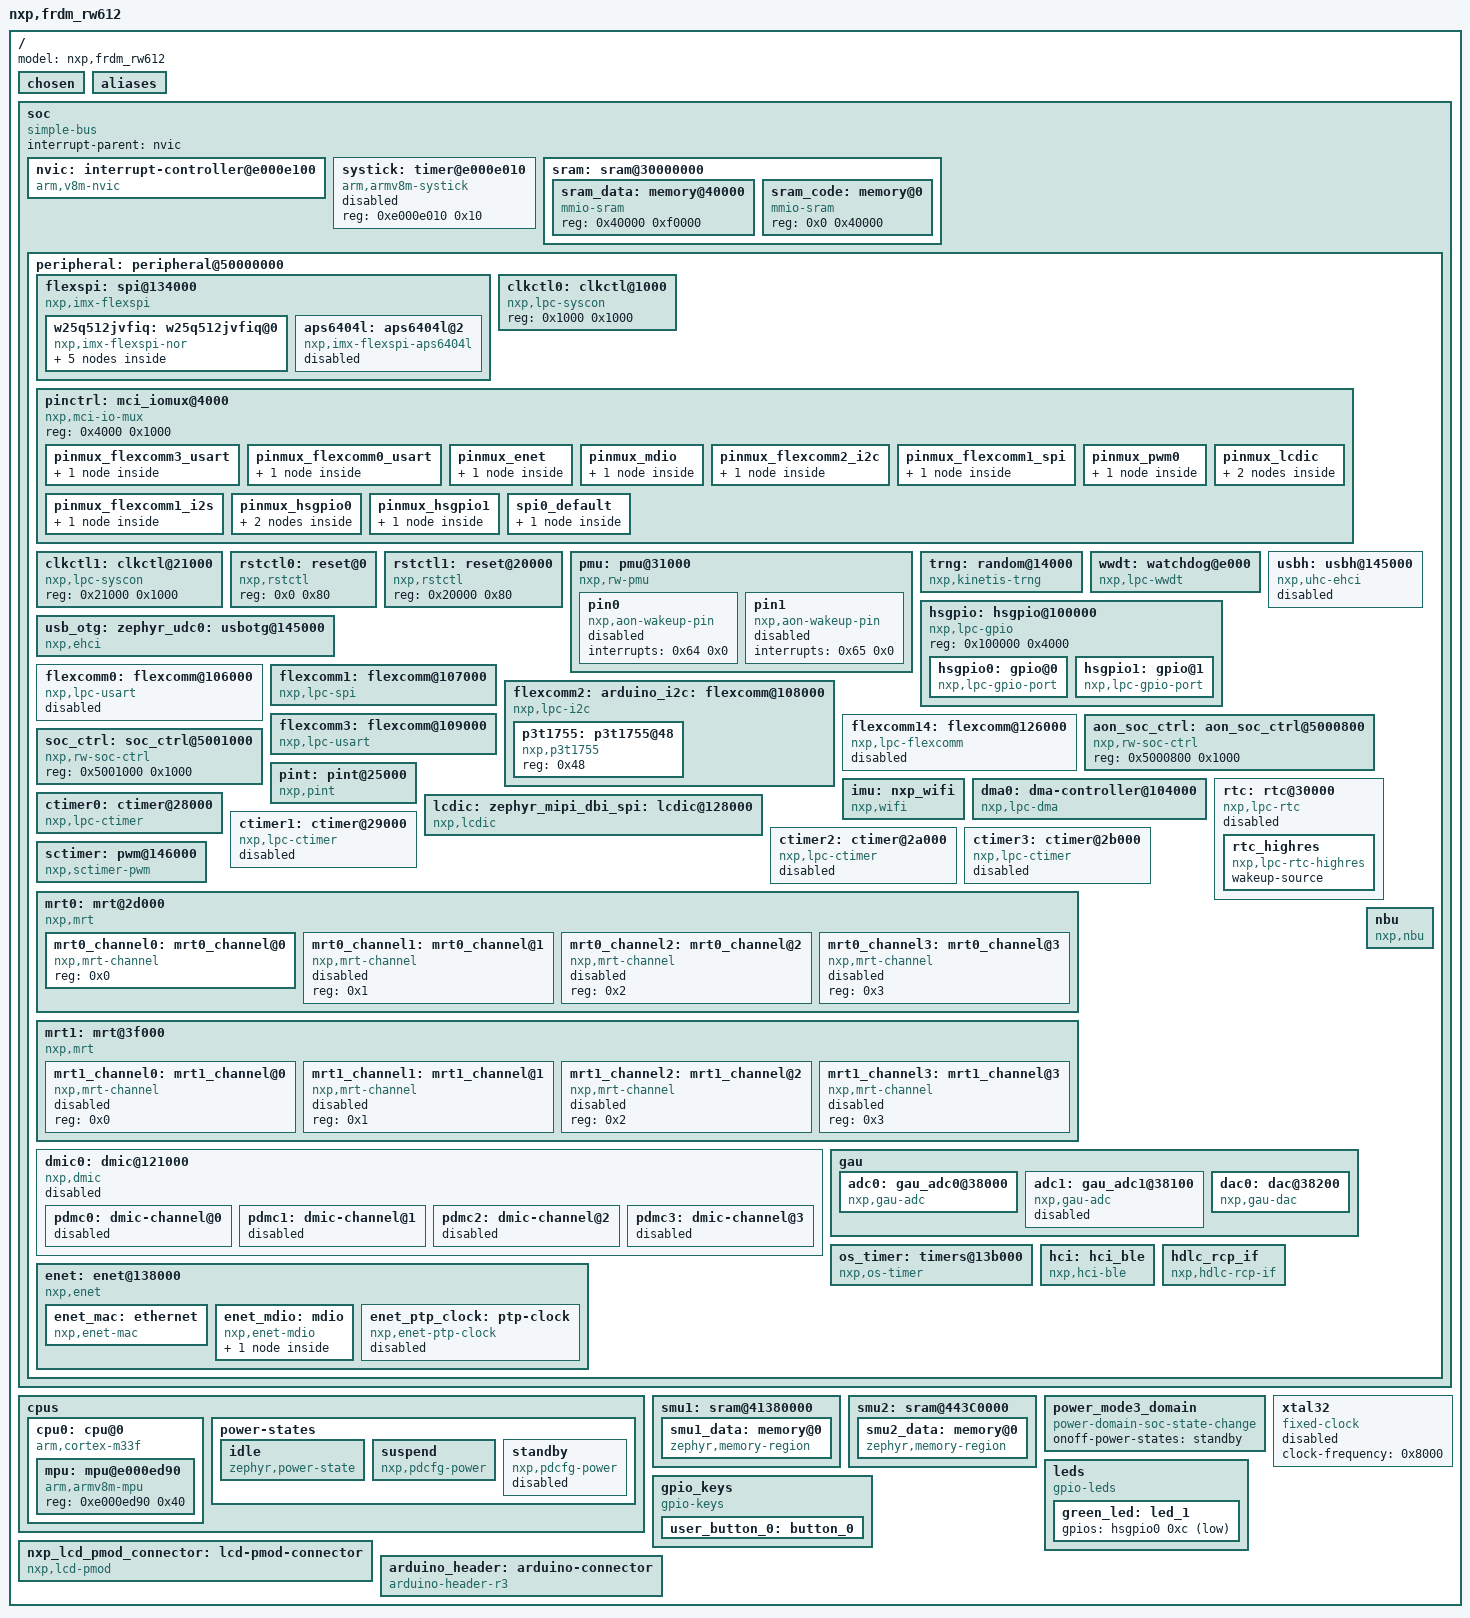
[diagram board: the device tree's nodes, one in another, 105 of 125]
/dts-v1/;

/* node '/' defined in zephyr/dts/common/skeleton.dtsi:9 */
/ {
	#address-cells = < 0x1 >; /* in zephyr/dts/common/skeleton.dtsi:10 */
	#size-cells = < 0x1 >;    /* in zephyr/dts/common/skeleton.dtsi:11 */
	model = "nxp,frdm_rw612"; /* in zephyr/boards/nxp/frdm_rw612/frdm_rw612_common.dtsi:12 */

	/* node '/chosen' defined in zephyr/dts/common/skeleton.dtsi:12 */
	chosen {
		zephyr,entropy = &trng;                   /* in zephyr/dts/arm/nxp/nxp_rw6xx_common.dtsi:18 */
		zephyr,nbu = &nbu;                        /* in zephyr/dts/arm/nxp/nxp_rw6xx_common.dtsi:19 */
		zephyr,bt-hci = &hci;                     /* in zephyr/dts/arm/nxp/nxp_rw6xx_common.dtsi:20 */
		zephyr,hdlc-rcp-if = &hdlc_rcp_if;        /* in zephyr/dts/arm/nxp/nxp_rw6xx_common.dtsi:21 */
		zephyr,sram = &sram_data;                 /* in zephyr/boards/nxp/frdm_rw612/frdm_rw612_common.dtsi:25 */
		zephyr,flash = &w25q512jvfiq;             /* in zephyr/boards/nxp/frdm_rw612/frdm_rw612_common.dtsi:26 */
		zephyr,console = &flexcomm3;              /* in zephyr/boards/nxp/frdm_rw612/frdm_rw612_common.dtsi:27 */
		zephyr,shell-uart = &flexcomm3;           /* in zephyr/boards/nxp/frdm_rw612/frdm_rw612_common.dtsi:28 */
		zephyr,flash-controller = &w25q512jvfiq;  /* in zephyr/boards/nxp/frdm_rw612/frdm_rw612_common.dtsi:29 */
		zephyr,code-partition = &slot0_partition; /* in zephyr/boards/nxp/frdm_rw612/frdm_rw612_common.dtsi:30 */
		zephyr,uart-mcumgr = &flexcomm3;          /* in zephyr/boards/nxp/frdm_rw612/frdm_rw612_common.dtsi:31 */
	};

	/* node '/aliases' defined in zephyr/dts/common/skeleton.dtsi:13 */
	aliases {
		led0 = &green_led;        /* in zephyr/boards/nxp/frdm_rw612/frdm_rw612_common.dtsi:15 */
		watchdog0 = &wwdt;        /* in zephyr/boards/nxp/frdm_rw612/frdm_rw612_common.dtsi:16 */
		usart-0 = &flexcomm3;     /* in zephyr/boards/nxp/frdm_rw612/frdm_rw612_common.dtsi:17 */
		i2c-0 = &flexcomm2;       /* in zephyr/boards/nxp/frdm_rw612/frdm_rw612_common.dtsi:18 */
		pwm-0 = &sctimer;         /* in zephyr/boards/nxp/frdm_rw612/frdm_rw612_common.dtsi:19 */
		sw0 = &user_button_0;     /* in zephyr/boards/nxp/frdm_rw612/frdm_rw612_common.dtsi:20 */
		ambient-temp0 = &p3t1755; /* in zephyr/boards/nxp/frdm_rw612/frdm_rw612_common.dtsi:21 */
		spi0 = &flexcomm1;        /* in ../dbus_porting/zephyr_dbus_driver/boards/frdm_rw612.overlay:3 */
	};

	/* node '/soc' defined in zephyr/dts/arm/armv8-m.dtsi:6 */
	soc {
		#address-cells = < 0x1 >;     /* in zephyr/dts/arm/armv8-m.dtsi:7 */
		#size-cells = < 0x1 >;        /* in zephyr/dts/arm/armv8-m.dtsi:8 */
		compatible = "simple-bus";    /* in zephyr/dts/arm/armv8-m.dtsi:9 */
		interrupt-parent = < &nvic >; /* in zephyr/dts/arm/armv8-m.dtsi:10 */
		ranges;                       /* in zephyr/dts/arm/armv8-m.dtsi:11 */

		/* node '/soc/interrupt-controller@e000e100' defined in zephyr/dts/arm/armv8-m.dtsi:13 */
		nvic: interrupt-controller@e000e100 {
			#address-cells = < 0x1 >;            /* in zephyr/dts/arm/armv8-m.dtsi:14 */
			compatible = "arm,v8m-nvic";         /* in zephyr/dts/arm/armv8-m.dtsi:15 */
			reg = < 0xe000e100 0xc00 >;          /* in zephyr/dts/arm/armv8-m.dtsi:16 */
			interrupt-controller;                /* in zephyr/dts/arm/armv8-m.dtsi:17 */
			#interrupt-cells = < 0x2 >;          /* in zephyr/dts/arm/armv8-m.dtsi:18 */
			arm,num-irq-priority-bits = < 0x3 >; /* in zephyr/dts/arm/nxp/nxp_rw6xx_common.dtsi:659 */
			phandle = < 0x1 >;                   /* in zephyr/dts/arm/armv8-m.dtsi:10 */
		};

		/* node '/soc/timer@e000e010' defined in zephyr/dts/arm/armv8-m.dtsi:21 */
		systick: timer@e000e010 {
			compatible = "arm,armv8m-systick"; /* in zephyr/dts/arm/armv8-m.dtsi:22 */
			reg = < 0xe000e010 0x10 >;         /* in zephyr/dts/arm/armv8-m.dtsi:23 */
			status = "disabled";               /* in zephyr/boards/nxp/frdm_rw612/frdm_rw612_common.dtsi:242 */
		};

		/* node '/soc/sram@30000000' defined in zephyr/dts/arm/nxp/nxp_rw6xx.dtsi:12 */
		sram: sram@30000000 {
			ranges = < 0x20000000 0x30000000 0x130000 0x0 0x10000000 0x130000 >; /* in zephyr/dts/arm/nxp/nxp_rw6xx.dtsi:13 */
			#address-cells = < 0x1 >;                                            /* in zephyr/dts/arm/nxp/nxp_rw6xx_common.dtsi:101 */
			#size-cells = < 0x1 >;                                               /* in zephyr/dts/arm/nxp/nxp_rw6xx_common.dtsi:102 */

			/* node '/soc/sram@30000000/memory@40000' defined in zephyr/dts/arm/nxp/nxp_rw6xx_common.dtsi:109 */
			sram_data: memory@40000 {
				compatible = "mmio-sram";  /* in zephyr/dts/arm/nxp/nxp_rw6xx_common.dtsi:110 */
				reg = < 0x40000 0xf0000 >; /* in zephyr/dts/arm/nxp/nxp_rw6xx_common.dtsi:111 */
			};

			/* node '/soc/sram@30000000/memory@0' defined in zephyr/dts/arm/nxp/nxp_rw6xx_common.dtsi:114 */
			sram_code: memory@0 {
				compatible = "mmio-sram"; /* in zephyr/dts/arm/nxp/nxp_rw6xx_common.dtsi:115 */
				reg = < 0x0 0x40000 >;    /* in zephyr/dts/arm/nxp/nxp_rw6xx_common.dtsi:116 */
			};
		};

		/* node '/soc/peripheral@50000000' defined in zephyr/dts/arm/nxp/nxp_rw6xx.dtsi:17 */
		peripheral: peripheral@50000000 {
			ranges = < 0x0 0x50000000 0x10000000 >; /* in zephyr/dts/arm/nxp/nxp_rw6xx.dtsi:18 */
			#address-cells = < 0x1 >;               /* in zephyr/dts/arm/nxp/nxp_rw6xx_common.dtsi:145 */
			#size-cells = < 0x1 >;                  /* in zephyr/dts/arm/nxp/nxp_rw6xx_common.dtsi:146 */

			/* node '/soc/peripheral@50000000/spi@134000' defined in zephyr/dts/arm/nxp/nxp_rw6xx_common.dtsi:148 */
			flexspi: spi@134000 {
				reg = < 0x134000 0x1000 >,
				      < 0x18000000 0x8000000 >; /* in zephyr/dts/arm/nxp/nxp_rw6xx_common.dtsi:149 */
				compatible = "nxp,imx-flexspi"; /* in zephyr/dts/arm/nxp/nxp_rw6xx_common.dtsi:650 */
				interrupts = < 0x2a 0x0 >;      /* in zephyr/dts/arm/nxp/nxp_rw6xx_common.dtsi:652 */
				#address-cells = < 0x1 >;       /* in zephyr/dts/arm/nxp/nxp_rw6xx_common.dtsi:653 */
				#size-cells = < 0x0 >;          /* in zephyr/dts/arm/nxp/nxp_rw6xx_common.dtsi:654 */
				clocks = < &clkctl1 0xa00 >;    /* in zephyr/dts/arm/nxp/nxp_rw6xx_common.dtsi:655 */
				status = "okay";                /* in zephyr/boards/nxp/frdm_rw612/frdm_rw612_common.dtsi:117 */
				ahb-bufferable;                 /* in zephyr/boards/nxp/frdm_rw612/frdm_rw612_common.dtsi:118 */
				ahb-prefetch;                   /* in zephyr/boards/nxp/frdm_rw612/frdm_rw612_common.dtsi:119 */
				ahb-cacheable;                  /* in zephyr/boards/nxp/frdm_rw612/frdm_rw612_common.dtsi:120 */
				ahb-read-addr-opt;              /* in zephyr/boards/nxp/frdm_rw612/frdm_rw612_common.dtsi:121 */
				ahb-boundary = "1024";          /* in zephyr/boards/nxp/frdm_rw612/frdm_rw612_common.dtsi:122 */
				rx-clock-source = < 0x1 >;      /* in zephyr/boards/nxp/frdm_rw612/frdm_rw612_common.dtsi:123 */
				rx-clock-source-b = < 0x1 >;    /* in zephyr/boards/nxp/frdm_rw612/frdm_rw612_common.dtsi:124 */

				/* node '/soc/peripheral@50000000/spi@134000/w25q512jvfiq@0' defined in zephyr/boards/nxp/frdm_rw612/frdm_rw612_common.dtsi:126 */
				w25q512jvfiq: w25q512jvfiq@0 {
					compatible = "nxp,imx-flexspi-nor"; /* in zephyr/boards/nxp/frdm_rw612/frdm_rw612_common.dtsi:127 */
					reg = < 0x0 >;                      /* in zephyr/boards/nxp/frdm_rw612/frdm_rw612_common.dtsi:128 */
					size = < 0x20000000 >;              /* in zephyr/boards/nxp/frdm_rw612/frdm_rw612_common.dtsi:129 */
					status = "okay";                    /* in zephyr/boards/nxp/frdm_rw612/frdm_rw612_common.dtsi:130 */
					jedec-id = [ EF 40 20 ];            /* in zephyr/boards/nxp/frdm_rw612/frdm_rw612_common.dtsi:131 */
					erase-block-size = < 0x1000 >;      /* in zephyr/boards/nxp/frdm_rw612/frdm_rw612_common.dtsi:132 */
					write-block-size = < 0x1 >;         /* in zephyr/boards/nxp/frdm_rw612/frdm_rw612_common.dtsi:133 */
					spi-max-frequency = < 0x632ea00 >;  /* in zephyr/boards/nxp/frdm_rw612/frdm_rw612_common.dtsi:134 */

					/* node '/soc/peripheral@50000000/spi@134000/w25q512jvfiq@0/partitions' defined in zephyr/boards/nxp/frdm_rw612/frdm_rw612_common.dtsi:136 */
					partitions {
						compatible = "fixed-partitions"; /* in zephyr/boards/nxp/frdm_rw612/frdm_rw612_common.dtsi:137 */
						#address-cells = < 0x1 >;        /* in zephyr/boards/nxp/frdm_rw612/frdm_rw612_common.dtsi:138 */
						#size-cells = < 0x1 >;           /* in zephyr/boards/nxp/frdm_rw612/frdm_rw612_common.dtsi:139 */

						/* node '/soc/peripheral@50000000/spi@134000/w25q512jvfiq@0/partitions/partition@0' defined in zephyr/boards/nxp/frdm_rw612/frdm_rw612_common.dtsi:145 */
						boot_partition: partition@0 {
							label = "mcuboot";     /* in zephyr/boards/nxp/frdm_rw612/frdm_rw612_common.dtsi:146 */
							reg = < 0x0 0x20000 >; /* in zephyr/boards/nxp/frdm_rw612/frdm_rw612_common.dtsi:147 */
						};

						/* node '/soc/peripheral@50000000/spi@134000/w25q512jvfiq@0/partitions/partition@20000' defined in zephyr/boards/nxp/frdm_rw612/frdm_rw612_common.dtsi:149 */
						slot0_partition: partition@20000 {
							label = "image-0";          /* in zephyr/boards/nxp/frdm_rw612/frdm_rw612_common.dtsi:150 */
							reg = < 0x20000 0x300000 >; /* in zephyr/boards/nxp/frdm_rw612/frdm_rw612_common.dtsi:151 */
						};

						/* node '/soc/peripheral@50000000/spi@134000/w25q512jvfiq@0/partitions/partition@320000' defined in zephyr/boards/nxp/frdm_rw612/frdm_rw612_common.dtsi:153 */
						slot1_partition: partition@320000 {
							label = "image-1";           /* in zephyr/boards/nxp/frdm_rw612/frdm_rw612_common.dtsi:154 */
							reg = < 0x320000 0x300000 >; /* in zephyr/boards/nxp/frdm_rw612/frdm_rw612_common.dtsi:155 */
						};

						/* node '/soc/peripheral@50000000/spi@134000/w25q512jvfiq@0/partitions/partition@620000' defined in zephyr/boards/nxp/frdm_rw612/frdm_rw612_common.dtsi:157 */
						storage_partition: partition@620000 {
							label = "storage";            /* in zephyr/boards/nxp/frdm_rw612/frdm_rw612_common.dtsi:158 */
							reg = < 0x620000 0x39e0000 >; /* in zephyr/boards/nxp/frdm_rw612/frdm_rw612_common.dtsi:159 */
						};
					};
				};

				/* node '/soc/peripheral@50000000/spi@134000/aps6404l@2' defined in zephyr/boards/nxp/frdm_rw612/frdm_rw612_common.dtsi:163 */
				aps6404l: aps6404l@2 {
					compatible = "nxp,imx-flexspi-aps6404l"; /* in zephyr/boards/nxp/frdm_rw612/frdm_rw612_common.dtsi:164 */
					size = < 0x4000000 >;                    /* in zephyr/boards/nxp/frdm_rw612/frdm_rw612_common.dtsi:166 */
					reg = < 0x2 >;                           /* in zephyr/boards/nxp/frdm_rw612/frdm_rw612_common.dtsi:167 */
					spi-max-frequency = < 0x67f3540 >;       /* in zephyr/boards/nxp/frdm_rw612/frdm_rw612_common.dtsi:168 */
					status = "disabled";                     /* in zephyr/boards/nxp/frdm_rw612/frdm_rw612_common.dtsi:172 */
					cs-interval-unit = < 0x1 >;              /* in zephyr/boards/nxp/frdm_rw612/frdm_rw612_common.dtsi:173 */
					cs-interval = < 0x2 >;                   /* in zephyr/boards/nxp/frdm_rw612/frdm_rw612_common.dtsi:174 */
					cs-hold-time = < 0x3 >;                  /* in zephyr/boards/nxp/frdm_rw612/frdm_rw612_common.dtsi:175 */
					cs-setup-time = < 0x3 >;                 /* in zephyr/boards/nxp/frdm_rw612/frdm_rw612_common.dtsi:176 */
					data-valid-time = < 0x6 >;               /* in zephyr/boards/nxp/frdm_rw612/frdm_rw612_common.dtsi:177 */
					column-space = < 0x0 >;                  /* in zephyr/boards/nxp/frdm_rw612/frdm_rw612_common.dtsi:178 */
					ahb-write-wait-unit = < 0x2 >;           /* in zephyr/boards/nxp/frdm_rw612/frdm_rw612_common.dtsi:179 */
					ahb-write-wait-interval = < 0x0 >;       /* in zephyr/boards/nxp/frdm_rw612/frdm_rw612_common.dtsi:180 */
				};
			};

			/* node '/soc/peripheral@50000000/clkctl@1000' defined in zephyr/dts/arm/nxp/nxp_rw6xx_common.dtsi:152 */
			clkctl0: clkctl@1000 {
				compatible = "nxp,lpc-syscon"; /* in zephyr/dts/arm/nxp/nxp_rw6xx_common.dtsi:154 */
				reg = < 0x1000 0x1000 >;       /* in zephyr/dts/arm/nxp/nxp_rw6xx_common.dtsi:155 */
				#clock-cells = < 0x1 >;        /* in zephyr/dts/arm/nxp/nxp_rw6xx_common.dtsi:156 */
			};

			/* node '/soc/peripheral@50000000/mci_iomux@4000' defined in zephyr/dts/arm/nxp/nxp_rw6xx_common.dtsi:159 */
			pinctrl: mci_iomux@4000 {
				compatible = "nxp,mci-io-mux"; /* in zephyr/dts/arm/nxp/nxp_rw6xx_common.dtsi:160 */
				reg = < 0x4000 0x1000 >;       /* in zephyr/dts/arm/nxp/nxp_rw6xx_common.dtsi:161 */
				status = "okay";               /* in zephyr/dts/arm/nxp/nxp_rw6xx_common.dtsi:162 */

				/* node '/soc/peripheral@50000000/mci_iomux@4000/pinmux_flexcomm3_usart' defined in zephyr/boards/nxp/frdm_rw612/frdm_rw612-pinctrl.dtsi:10 */
				pinmux_flexcomm3_usart: pinmux_flexcomm3_usart {
					phandle = < 0xd >; /* in zephyr/boards/nxp/frdm_rw612/frdm_rw612_common.dtsi:91 */

					/* node '/soc/peripheral@50000000/mci_iomux@4000/pinmux_flexcomm3_usart/group0' defined in zephyr/boards/nxp/frdm_rw612/frdm_rw612-pinctrl.dtsi:11 */
					group0 {
						pinmux = < 0x49818 0x4981a >; /* in zephyr/boards/nxp/frdm_rw612/frdm_rw612-pinctrl.dtsi:12 */
						slew-rate = "normal";         /* in zephyr/boards/nxp/frdm_rw612/frdm_rw612-pinctrl.dtsi:13 */
					};
				};

				/* node '/soc/peripheral@50000000/mci_iomux@4000/pinmux_flexcomm0_usart' defined in zephyr/boards/nxp/frdm_rw612/frdm_rw612-pinctrl.dtsi:17 */
				pinmux_flexcomm0_usart: pinmux_flexcomm0_usart {
					phandle = < 0xa >; /* in zephyr/boards/nxp/frdm_rw612/frdm_rw612_common.dtsi:100 */

					/* node '/soc/peripheral@50000000/mci_iomux@4000/pinmux_flexcomm0_usart/group0' defined in zephyr/boards/nxp/frdm_rw612/frdm_rw612-pinctrl.dtsi:18 */
					group0 {
						pinmux = < 0x48002 0x48003 >; /* in zephyr/boards/nxp/frdm_rw612/frdm_rw612-pinctrl.dtsi:19 */
						slew-rate = "normal";         /* in zephyr/boards/nxp/frdm_rw612/frdm_rw612-pinctrl.dtsi:20 */
					};
				};

				/* node '/soc/peripheral@50000000/mci_iomux@4000/pinmux_enet' defined in zephyr/boards/nxp/frdm_rw612/frdm_rw612-pinctrl.dtsi:24 */
				pinmux_enet: pinmux_enet {
					phandle = < 0x14 >; /* in zephyr/boards/nxp/frdm_rw612/frdm_rw612_common.dtsi:191 */

					/* node '/soc/peripheral@50000000/mci_iomux@4000/pinmux_enet/group0' defined in zephyr/boards/nxp/frdm_rw612/frdm_rw612-pinctrl.dtsi:25 */
					group0 {
						pinmux = < 0x8099 0xd096 0xd097 0xd0be 0xd0bf 0xc8ba 0xc8bb 0xc8bc 0x315 0x337 >; /* in zephyr/boards/nxp/frdm_rw612/frdm_rw612-pinctrl.dtsi:26 */
						slew-rate = "fast";                                                               /* in zephyr/boards/nxp/frdm_rw612/frdm_rw612-pinctrl.dtsi:31 */
					};
				};

				/* node '/soc/peripheral@50000000/mci_iomux@4000/pinmux_mdio' defined in zephyr/boards/nxp/frdm_rw612/frdm_rw612-pinctrl.dtsi:35 */
				pinmux_mdio: pinmux_mdio {
					phandle = < 0x16 >; /* in zephyr/boards/nxp/frdm_rw612/frdm_rw612_common.dtsi:200 */

					/* node '/soc/peripheral@50000000/mci_iomux@4000/pinmux_mdio/group0' defined in zephyr/boards/nxp/frdm_rw612/frdm_rw612-pinctrl.dtsi:36 */
					group0 {
						pinmux = < 0xd8b8 0xd8b9 >; /* in zephyr/boards/nxp/frdm_rw612/frdm_rw612-pinctrl.dtsi:37 */
						slew-rate = "fast";         /* in zephyr/boards/nxp/frdm_rw612/frdm_rw612-pinctrl.dtsi:38 */
					};
				};

				/* node '/soc/peripheral@50000000/mci_iomux@4000/pinmux_flexcomm2_i2c' defined in zephyr/boards/nxp/frdm_rw612/frdm_rw612-pinctrl.dtsi:42 */
				pinmux_flexcomm2_i2c: pinmux_flexcomm2_i2c {
					phandle = < 0xc >; /* in zephyr/boards/nxp/frdm_rw612/frdm_rw612_common.dtsi:300 */

					/* node '/soc/peripheral@50000000/mci_iomux@4000/pinmux_flexcomm2_i2c/group0' defined in zephyr/boards/nxp/frdm_rw612/frdm_rw612-pinctrl.dtsi:43 */
					group0 {
						pinmux = < 0x21010 0x21011 >; /* in zephyr/boards/nxp/frdm_rw612/frdm_rw612-pinctrl.dtsi:44 */
						slew-rate = "normal";         /* in zephyr/boards/nxp/frdm_rw612/frdm_rw612-pinctrl.dtsi:45 */
						bias-pull-up;                 /* in zephyr/boards/nxp/frdm_rw612/frdm_rw612-pinctrl.dtsi:46 */
					};
				};

				/* node '/soc/peripheral@50000000/mci_iomux@4000/pinmux_flexcomm1_spi' defined in zephyr/boards/nxp/frdm_rw612/frdm_rw612-pinctrl.dtsi:50 */
				pinmux_flexcomm1_spi: pinmux_flexcomm1_spi {
					phandle = < 0xb >; /* in zephyr/boards/nxp/frdm_rw612/frdm_rw612_common.dtsi:287 */

					/* node '/soc/peripheral@50000000/mci_iomux@4000/pinmux_flexcomm1_spi/group0' defined in zephyr/boards/nxp/frdm_rw612/frdm_rw612-pinctrl.dtsi:51 */
					group0 {
						pinmux = < 0x18806 0x18807 0x18808 0x18809 >; /* in zephyr/boards/nxp/frdm_rw612/frdm_rw612-pinctrl.dtsi:52 */
						slew-rate = "ultra";                          /* in zephyr/boards/nxp/frdm_rw612/frdm_rw612-pinctrl.dtsi:53 */
					};
				};

				/* node '/soc/peripheral@50000000/mci_iomux@4000/pinmux_pwm0' defined in zephyr/boards/nxp/frdm_rw612/frdm_rw612-pinctrl.dtsi:57 */
				pinmux_pwm0: pinmux_pwm0 {
					phandle = < 0xf >; /* in zephyr/boards/nxp/frdm_rw612/frdm_rw612_common.dtsi:255 */

					/* node '/soc/peripheral@50000000/mci_iomux@4000/pinmux_pwm0/group0' defined in zephyr/boards/nxp/frdm_rw612/frdm_rw612-pinctrl.dtsi:58 */
					group0 {
						pinmux = < 0x283 >;   /* in zephyr/boards/nxp/frdm_rw612/frdm_rw612-pinctrl.dtsi:59 */
						slew-rate = "normal"; /* in zephyr/boards/nxp/frdm_rw612/frdm_rw612-pinctrl.dtsi:60 */
					};
				};

				/* node '/soc/peripheral@50000000/mci_iomux@4000/pinmux_lcdic' defined in zephyr/boards/nxp/frdm_rw612/frdm_rw612-pinctrl.dtsi:64 */
				pinmux_lcdic: pinmux_lcdic {
					phandle = < 0xe >; /* in zephyr/boards/nxp/frdm_rw612/frdm_rw612_common.dtsi:312 */

					/* node '/soc/peripheral@50000000/mci_iomux@4000/pinmux_lcdic/group0' defined in zephyr/boards/nxp/frdm_rw612/frdm_rw612-pinctrl.dtsi:65 */
					group0 {
						pinmux = < 0x60ad 0x60ae 0x60af 0x60b0 0x60b1 >; /* in zephyr/boards/nxp/frdm_rw612/frdm_rw612-pinctrl.dtsi:66 */
						slew-rate = "ultra";                             /* in zephyr/boards/nxp/frdm_rw612/frdm_rw612-pinctrl.dtsi:71 */
					};

					/* node '/soc/peripheral@50000000/mci_iomux@4000/pinmux_lcdic/group1' defined in zephyr/boards/nxp/frdm_rw612/frdm_rw612-pinctrl.dtsi:73 */
					group1 {
						pinmux = < 0x60ac >;   /* in zephyr/boards/nxp/frdm_rw612/frdm_rw612-pinctrl.dtsi:74 */
						slew-rate = "ultra";   /* in zephyr/boards/nxp/frdm_rw612/frdm_rw612-pinctrl.dtsi:75 */
						sleep-output = "high"; /* in zephyr/boards/nxp/frdm_rw612/frdm_rw612-pinctrl.dtsi:76 */
					};
				};

				/* node '/soc/peripheral@50000000/mci_iomux@4000/pinmux_flexcomm1_i2s' defined in zephyr/boards/nxp/frdm_rw612/frdm_rw612-pinctrl.dtsi:80 */
				pinmux_flexcomm1_i2s: pinmux_flexcomm1_i2s {

					/* node '/soc/peripheral@50000000/mci_iomux@4000/pinmux_flexcomm1_i2s/group0' defined in zephyr/boards/nxp/frdm_rw612/frdm_rw612-pinctrl.dtsi:81 */
					group0 {
						pinmux = < 0x10807 0x10808 0x10809 >; /* in zephyr/boards/nxp/frdm_rw612/frdm_rw612-pinctrl.dtsi:82 */
						slew-rate = "normal";                 /* in zephyr/boards/nxp/frdm_rw612/frdm_rw612-pinctrl.dtsi:83 */
					};
				};

				/* node '/soc/peripheral@50000000/mci_iomux@4000/pinmux_hsgpio0' defined in zephyr/boards/nxp/frdm_rw612/frdm_rw612-pinctrl.dtsi:87 */
				pinmux_hsgpio0: pinmux_hsgpio0 {
					phandle = < 0x4 >; /* in zephyr/boards/nxp/frdm_rw612/frdm_rw612_common.dtsi:106 */

					/* node '/soc/peripheral@50000000/mci_iomux@4000/pinmux_hsgpio0/group0' defined in zephyr/boards/nxp/frdm_rw612/frdm_rw612-pinctrl.dtsi:88 */
					group0 {
						pinmux = < 0x30b 0x312 0x315 >; /* in zephyr/boards/nxp/frdm_rw612/frdm_rw612-pinctrl.dtsi:89 */
						slew-rate = "normal";           /* in zephyr/boards/nxp/frdm_rw612/frdm_rw612-pinctrl.dtsi:93 */
					};

					/* node '/soc/peripheral@50000000/mci_iomux@4000/pinmux_hsgpio0/group1' defined in zephyr/boards/nxp/frdm_rw612/frdm_rw612-pinctrl.dtsi:95 */
					group1 {
						pinmux = < 0x300 0x301 0x30c >; /* in zephyr/boards/nxp/frdm_rw612/frdm_rw612-pinctrl.dtsi:96 */
						slew-rate = "normal";           /* in zephyr/boards/nxp/frdm_rw612/frdm_rw612-pinctrl.dtsi:100 */
						sleep-output = "high";          /* in zephyr/boards/nxp/frdm_rw612/frdm_rw612-pinctrl.dtsi:101 */
					};
				};

				/* node '/soc/peripheral@50000000/mci_iomux@4000/pinmux_hsgpio1' defined in zephyr/boards/nxp/frdm_rw612/frdm_rw612-pinctrl.dtsi:105 */
				pinmux_hsgpio1: pinmux_hsgpio1 {
					phandle = < 0x5 >; /* in zephyr/boards/nxp/frdm_rw612/frdm_rw612_common.dtsi:112 */

					/* node '/soc/peripheral@50000000/mci_iomux@4000/pinmux_hsgpio1/group0' defined in zephyr/boards/nxp/frdm_rw612/frdm_rw612-pinctrl.dtsi:106 */
					group0 {
						pinmux = < 0x32c 0x337 >; /* in zephyr/boards/nxp/frdm_rw612/frdm_rw612-pinctrl.dtsi:107 */
						slew-rate = "normal";     /* in zephyr/boards/nxp/frdm_rw612/frdm_rw612-pinctrl.dtsi:110 */
					};
				};

				/* node '/soc/peripheral@50000000/mci_iomux@4000/spi0_default' defined in ../dbus_porting/zephyr_dbus_driver/boards/frdm_rw612.overlay:8 */
				spi0_default: spi0_default {

					/* node '/soc/peripheral@50000000/mci_iomux@4000/spi0_default/group-0' defined in ../dbus_porting/zephyr_dbus_driver/boards/frdm_rw612.overlay:9 */
					group-0 {
						pinmux = < 0x18806 0x18807 0x18808 0x18809 >; /* in ../dbus_porting/zephyr_dbus_driver/boards/frdm_rw612.overlay:10 */
						slew-rate = "ultra";                          /* in ../dbus_porting/zephyr_dbus_driver/boards/frdm_rw612.overlay:11 */
					};
				};
			};

			/* node '/soc/peripheral@50000000/clkctl@21000' defined in zephyr/dts/arm/nxp/nxp_rw6xx_common.dtsi:165 */
			clkctl1: clkctl@21000 {
				compatible = "nxp,lpc-syscon"; /* in zephyr/dts/arm/nxp/nxp_rw6xx_common.dtsi:167 */
				reg = < 0x21000 0x1000 >;      /* in zephyr/dts/arm/nxp/nxp_rw6xx_common.dtsi:168 */
				#clock-cells = < 0x1 >;        /* in zephyr/dts/arm/nxp/nxp_rw6xx_common.dtsi:169 */
				phandle = < 0x2 >;             /* in zephyr/dts/arm/nxp/nxp_rw6xx_common.dtsi:655 */
			};

			/* node '/soc/peripheral@50000000/reset@0' defined in zephyr/dts/arm/nxp/nxp_rw6xx_common.dtsi:172 */
			rstctl0: reset@0 {
				compatible = "nxp,rstctl"; /* in zephyr/dts/arm/nxp/nxp_rw6xx_common.dtsi:173 */
				reg = < 0x0 0x80 >;        /* in zephyr/dts/arm/nxp/nxp_rw6xx_common.dtsi:174 */
				#reset-cells = < 0x1 >;    /* in zephyr/dts/arm/nxp/nxp_rw6xx_common.dtsi:175 */
				phandle = < 0x10 >;        /* in zephyr/dts/arm/nxp/nxp_rw6xx_common.dtsi:499 */
			};

			/* node '/soc/peripheral@50000000/reset@20000' defined in zephyr/dts/arm/nxp/nxp_rw6xx_common.dtsi:178 */
			rstctl1: reset@20000 {
				compatible = "nxp,rstctl"; /* in zephyr/dts/arm/nxp/nxp_rw6xx_common.dtsi:179 */
				reg = < 0x20000 0x80 >;    /* in zephyr/dts/arm/nxp/nxp_rw6xx_common.dtsi:180 */
				#reset-cells = < 0x1 >;    /* in zephyr/dts/arm/nxp/nxp_rw6xx_common.dtsi:181 */
				phandle = < 0x6 >;         /* in zephyr/dts/arm/nxp/nxp_rw6xx_common.dtsi:266 */
			};

			/* node '/soc/peripheral@50000000/pmu@31000' defined in zephyr/dts/arm/nxp/nxp_rw6xx_common.dtsi:184 */
			pmu: pmu@31000 {
				reg = < 0x31000 0x130 >;    /* in zephyr/dts/arm/nxp/nxp_rw6xx_common.dtsi:185 */
				compatible = "nxp,rw-pmu";  /* in zephyr/dts/arm/nxp/nxp_rw6xx_common.dtsi:186 */
				reset-causes-en = < 0x2 >,
				                  < 0x20 >,
				                  < 0x8 >;  /* in zephyr/boards/nxp/frdm_rw612/frdm_rw612_common.dtsi:229 */

				/* node '/soc/peripheral@50000000/pmu@31000/pin0' defined in zephyr/dts/arm/nxp/nxp_rw6xx_common.dtsi:187 */
				pin0: pin0 {
					compatible = "nxp,aon-wakeup-pin"; /* in zephyr/dts/arm/nxp/nxp_rw6xx_common.dtsi:188 */
					interrupts = < 0x64 0x0 >;         /* in zephyr/dts/arm/nxp/nxp_rw6xx_common.dtsi:189 */
					status = "disabled";               /* in zephyr/dts/arm/nxp/nxp_rw6xx_common.dtsi:190 */
				};

				/* node '/soc/peripheral@50000000/pmu@31000/pin1' defined in zephyr/dts/arm/nxp/nxp_rw6xx_common.dtsi:192 */
				pin1: pin1 {
					compatible = "nxp,aon-wakeup-pin"; /* in zephyr/dts/arm/nxp/nxp_rw6xx_common.dtsi:193 */
					interrupts = < 0x65 0x0 >;         /* in zephyr/dts/arm/nxp/nxp_rw6xx_common.dtsi:194 */
					status = "disabled";               /* in zephyr/dts/arm/nxp/nxp_rw6xx_common.dtsi:195 */
				};
			};

			/* node '/soc/peripheral@50000000/random@14000' defined in zephyr/dts/arm/nxp/nxp_rw6xx_common.dtsi:199 */
			trng: random@14000 {
				compatible = "nxp,kinetis-trng";         /* in zephyr/dts/arm/nxp/nxp_rw6xx_common.dtsi:200 */
				reg = < 0x14000 0x1000 >;                /* in zephyr/dts/arm/nxp/nxp_rw6xx_common.dtsi:201 */
				status = "okay";                         /* in zephyr/dts/arm/nxp/nxp_rw6xx_common.dtsi:202 */
				interrupts = < 0x7b 0x0 >;               /* in zephyr/dts/arm/nxp/nxp_rw6xx_common.dtsi:203 */
				power-domains = < &power_mode3_domain >; /* in zephyr/dts/arm/nxp/nxp_rw6xx_common.dtsi:204 */
			};

			/* node '/soc/peripheral@50000000/watchdog@e000' defined in zephyr/dts/arm/nxp/nxp_rw6xx_common.dtsi:207 */
			wwdt: watchdog@e000 {
				compatible = "nxp,lpc-wwdt";             /* in zephyr/dts/arm/nxp/nxp_rw6xx_common.dtsi:208 */
				reg = < 0xe000 0x1000 >;                 /* in zephyr/dts/arm/nxp/nxp_rw6xx_common.dtsi:209 */
				interrupts = < 0x0 0x0 >;                /* in zephyr/dts/arm/nxp/nxp_rw6xx_common.dtsi:210 */
				power-domains = < &power_mode3_domain >; /* in zephyr/dts/arm/nxp/nxp_rw6xx_common.dtsi:212 */
				clk-divider = < 0x1 >;                   /* in zephyr/dts/arm/nxp/nxp_rw6xx_common.dtsi:213 */
				status = "okay";                         /* in zephyr/boards/nxp/frdm_rw612/frdm_rw612_common.dtsi:213 */
			};

			/* node '/soc/peripheral@50000000/hsgpio@100000' defined in zephyr/dts/arm/nxp/nxp_rw6xx_common.dtsi:216 */
			hsgpio: hsgpio@100000 {
				compatible = "nxp,lpc-gpio"; /* in zephyr/dts/arm/nxp/nxp_rw6xx_common.dtsi:217 */
				reg = < 0x100000 0x4000 >;   /* in zephyr/dts/arm/nxp/nxp_rw6xx_common.dtsi:218 */
				#address-cells = < 0x1 >;    /* in zephyr/dts/arm/nxp/nxp_rw6xx_common.dtsi:219 */
				#size-cells = < 0x0 >;       /* in zephyr/dts/arm/nxp/nxp_rw6xx_common.dtsi:220 */

				/* node '/soc/peripheral@50000000/hsgpio@100000/gpio@0' defined in zephyr/dts/arm/nxp/nxp_rw6xx_common.dtsi:222 */
				hsgpio0: gpio@0 {
					compatible = "nxp,lpc-gpio-port";        /* in zephyr/dts/arm/nxp/nxp_rw6xx_common.dtsi:223 */
					gpio-controller;                         /* in zephyr/dts/arm/nxp/nxp_rw6xx_common.dtsi:224 */
					#gpio-cells = < 0x2 >;                   /* in zephyr/dts/arm/nxp/nxp_rw6xx_common.dtsi:225 */
					reg = < 0x0 >;                           /* in zephyr/dts/arm/nxp/nxp_rw6xx_common.dtsi:226 */
					int-source = "pint";                     /* in zephyr/dts/arm/nxp/nxp_rw6xx_common.dtsi:227 */
					power-domains = < &power_mode3_domain >; /* in zephyr/dts/arm/nxp/nxp_rw6xx_common.dtsi:228 */
					status = "okay";                         /* in zephyr/boards/nxp/frdm_rw612/frdm_rw612_common.dtsi:105 */
					pinctrl-0 = < &pinmux_hsgpio0 >;         /* in zephyr/boards/nxp/frdm_rw612/frdm_rw612_common.dtsi:106 */
					pinctrl-names = "default";               /* in zephyr/boards/nxp/frdm_rw612/frdm_rw612_common.dtsi:107 */
					phandle = < 0x18 >;                      /* in zephyr/boards/nxp/frdm_rw612/frdm_rw612_common.dtsi:207 */
				};

				/* node '/soc/peripheral@50000000/hsgpio@100000/gpio@1' defined in zephyr/dts/arm/nxp/nxp_rw6xx_common.dtsi:231 */
				hsgpio1: gpio@1 {
					compatible = "nxp,lpc-gpio-port";        /* in zephyr/dts/arm/nxp/nxp_rw6xx_common.dtsi:232 */
					gpio-controller;                         /* in zephyr/dts/arm/nxp/nxp_rw6xx_common.dtsi:233 */
					#gpio-cells = < 0x2 >;                   /* in zephyr/dts/arm/nxp/nxp_rw6xx_common.dtsi:234 */
					reg = < 0x1 >;                           /* in zephyr/dts/arm/nxp/nxp_rw6xx_common.dtsi:235 */
					int-source = "pint";                     /* in zephyr/dts/arm/nxp/nxp_rw6xx_common.dtsi:236 */
					power-domains = < &power_mode3_domain >; /* in zephyr/dts/arm/nxp/nxp_rw6xx_common.dtsi:237 */
					status = "okay";                         /* in zephyr/boards/nxp/frdm_rw612/frdm_rw612_common.dtsi:111 */
					pinctrl-0 = < &pinmux_hsgpio1 >;         /* in zephyr/boards/nxp/frdm_rw612/frdm_rw612_common.dtsi:112 */
					pinctrl-names = "default";               /* in zephyr/boards/nxp/frdm_rw612/frdm_rw612_common.dtsi:113 */
					phandle = < 0x17 >;                      /* in zephyr/boards/nxp/frdm_rw612/frdm_rw612_common.dtsi:206 */
				};
			};

			/* node '/soc/peripheral@50000000/usbotg@145000' defined in zephyr/dts/arm/nxp/nxp_rw6xx_common.dtsi:241 */
			usb_otg: zephyr_udc0: usbotg@145000 {
				compatible = "nxp,ehci";                 /* in zephyr/dts/arm/nxp/nxp_rw6xx_common.dtsi:242 */
				reg = < 0x145000 0x200 >;                /* in zephyr/dts/arm/nxp/nxp_rw6xx_common.dtsi:243 */
				interrupts = < 0x32 0x1 >;               /* in zephyr/dts/arm/nxp/nxp_rw6xx_common.dtsi:244 */
				interrupt-names = "usb_otg";             /* in zephyr/dts/arm/nxp/nxp_rw6xx_common.dtsi:245 */
				num-bidir-endpoints = < 0x8 >;           /* in zephyr/dts/arm/nxp/nxp_rw6xx_common.dtsi:246 */
				power-domains = < &power_mode3_domain >; /* in zephyr/dts/arm/nxp/nxp_rw6xx_common.dtsi:247 */
				status = "okay";                         /* in zephyr/boards/nxp/frdm_rw612/frdm_rw612_common.dtsi:276 */
			};

			/* node '/soc/peripheral@50000000/usbh@145000' defined in zephyr/dts/arm/nxp/nxp_rw6xx_common.dtsi:251 */
			usbh: usbh@145000 {
				compatible = "nxp,uhc-ehci";             /* in zephyr/dts/arm/nxp/nxp_rw6xx_common.dtsi:252 */
				reg = < 0x145000 0x200 >;                /* in zephyr/dts/arm/nxp/nxp_rw6xx_common.dtsi:253 */
				interrupts = < 0x32 0x1 >;               /* in zephyr/dts/arm/nxp/nxp_rw6xx_common.dtsi:254 */
				interrupt-names = "usb_otg";             /* in zephyr/dts/arm/nxp/nxp_rw6xx_common.dtsi:255 */
				power-domains = < &power_mode3_domain >; /* in zephyr/dts/arm/nxp/nxp_rw6xx_common.dtsi:256 */
				status = "disabled";                     /* in zephyr/dts/arm/nxp/nxp_rw6xx_common.dtsi:257 */
			};

			/* node '/soc/peripheral@50000000/flexcomm@106000' defined in zephyr/dts/arm/nxp/nxp_rw6xx_common.dtsi:260 */
			flexcomm0: flexcomm@106000 {
				reg = < 0x106000 0x1000 >;                             /* in zephyr/dts/arm/nxp/nxp_rw6xx_common.dtsi:262 */
				interrupts = < 0xe 0x0 >;                              /* in zephyr/dts/arm/nxp/nxp_rw6xx_common.dtsi:263 */
				clocks = < &clkctl1 0x100 &clkctl1 0x180 >;            /* in zephyr/dts/arm/nxp/nxp_rw6xx_common.dtsi:264 */
				clock-names = "default",
				              "sleep";                                 /* in zephyr/dts/arm/nxp/nxp_rw6xx_common.dtsi:265 */
				resets = < &rstctl1 0x8 >;                             /* in zephyr/dts/arm/nxp/nxp_rw6xx_common.dtsi:266 */
				dmas = < &dma0 0x0 >,
				       < &dma0 0x1 >;                                  /* in zephyr/dts/arm/nxp/nxp_rw6xx_common.dtsi:267 */
				dma-names = "rx",
				            "tx";                                      /* in zephyr/dts/arm/nxp/nxp_rw6xx_common.dtsi:268 */
				zephyr,disabling-power-states = < &suspend &standby >; /* in zephyr/dts/arm/nxp/nxp_rw6xx_common.dtsi:269 */
				power-domains = < &power_mode3_domain >;               /* in zephyr/dts/arm/nxp/nxp_rw6xx_common.dtsi:270 */
				compatible = "nxp,lpc-usart";                          /* in zephyr/boards/nxp/frdm_rw612/frdm_rw612_common.dtsi:97 */
				status = "disabled";                                   /* in zephyr/boards/nxp/frdm_rw612/frdm_rw612_common.dtsi:98 */
				current-speed = < 0x1c200 >;                           /* in zephyr/boards/nxp/frdm_rw612/frdm_rw612_common.dtsi:99 */
				pinctrl-0 = < &pinmux_flexcomm0_usart >;               /* in zephyr/boards/nxp/frdm_rw612/frdm_rw612_common.dtsi:100 */
				pinctrl-names = "default";                             /* in zephyr/boards/nxp/frdm_rw612/frdm_rw612_common.dtsi:101 */
			};

			/* node '/soc/peripheral@50000000/flexcomm@107000' defined in zephyr/dts/arm/nxp/nxp_rw6xx_common.dtsi:274 */
			flexcomm1: flexcomm@107000 {
				reg = < 0x107000 0x1000 >;                             /* in zephyr/dts/arm/nxp/nxp_rw6xx_common.dtsi:276 */
				interrupts = < 0xf 0x0 >;                              /* in zephyr/dts/arm/nxp/nxp_rw6xx_common.dtsi:277 */
				clocks = < &clkctl1 0x101 &clkctl1 0x181 >;            /* in zephyr/dts/arm/nxp/nxp_rw6xx_common.dtsi:278 */
				clock-names = "default",
				              "sleep";                                 /* in zephyr/dts/arm/nxp/nxp_rw6xx_common.dtsi:279 */
				resets = < &rstctl1 0x9 >;                             /* in zephyr/dts/arm/nxp/nxp_rw6xx_common.dtsi:280 */
				dmas = < &dma0 0x2 >,
				       < &dma0 0x3 >;                                  /* in zephyr/dts/arm/nxp/nxp_rw6xx_common.dtsi:281 */
				dma-names = "rx",
				            "tx";                                      /* in zephyr/dts/arm/nxp/nxp_rw6xx_common.dtsi:282 */
				zephyr,disabling-power-states = < &suspend &standby >; /* in zephyr/dts/arm/nxp/nxp_rw6xx_common.dtsi:283 */
				power-domains = < &power_mode3_domain >;               /* in zephyr/dts/arm/nxp/nxp_rw6xx_common.dtsi:284 */
				compatible = "nxp,lpc-spi";                            /* in zephyr/boards/nxp/frdm_rw612/frdm_rw612_common.dtsi:286 */
				pinctrl-0 = < &pinmux_flexcomm1_spi >;                 /* in zephyr/boards/nxp/frdm_rw612/frdm_rw612_common.dtsi:287 */
				pinctrl-names = "default";                             /* in zephyr/boards/nxp/frdm_rw612/frdm_rw612_common.dtsi:288 */
				status = "okay";                                       /* in zephyr/boards/nxp/frdm_rw612/frdm_rw612_common.dtsi:289 */
				#address-cells = < 0x1 >;                              /* in zephyr/boards/nxp/frdm_rw612/frdm_rw612_common.dtsi:290 */
				#size-cells = < 0x0 >;                                 /* in zephyr/boards/nxp/frdm_rw612/frdm_rw612_common.dtsi:291 */
			};

			/* node '/soc/peripheral@50000000/flexcomm@108000' defined in zephyr/dts/arm/nxp/nxp_rw6xx_common.dtsi:288 */
			flexcomm2: arduino_i2c: nxp_pmod_touch_panel_i2c: flexcomm@108000 {
				reg = < 0x108000 0x1000 >;                             /* in zephyr/dts/arm/nxp/nxp_rw6xx_common.dtsi:290 */
				interrupts = < 0x10 0x0 >;                             /* in zephyr/dts/arm/nxp/nxp_rw6xx_common.dtsi:291 */
				clocks = < &clkctl1 0x102 &clkctl1 0x182 >;            /* in zephyr/dts/arm/nxp/nxp_rw6xx_common.dtsi:292 */
				clock-names = "default",
				              "sleep";                                 /* in zephyr/dts/arm/nxp/nxp_rw6xx_common.dtsi:293 */
				resets = < &rstctl1 0xa >;                             /* in zephyr/dts/arm/nxp/nxp_rw6xx_common.dtsi:294 */
				dmas = < &dma0 0x4 >,
				       < &dma0 0x5 >;                                  /* in zephyr/dts/arm/nxp/nxp_rw6xx_common.dtsi:295 */
				dma-names = "rx",
				            "tx";                                      /* in zephyr/dts/arm/nxp/nxp_rw6xx_common.dtsi:296 */
				zephyr,disabling-power-states = < &suspend &standby >; /* in zephyr/dts/arm/nxp/nxp_rw6xx_common.dtsi:297 */
				power-domains = < &power_mode3_domain >;               /* in zephyr/dts/arm/nxp/nxp_rw6xx_common.dtsi:298 */
				compatible = "nxp,lpc-i2c";                            /* in zephyr/boards/nxp/frdm_rw612/frdm_rw612_common.dtsi:295 */
				clock-frequency = < 0x61a80 >;                         /* in zephyr/boards/nxp/frdm_rw612/frdm_rw612_common.dtsi:297 */
				#address-cells = < 0x1 >;                              /* in zephyr/boards/nxp/frdm_rw612/frdm_rw612_common.dtsi:298 */
				#size-cells = < 0x0 >;                                 /* in zephyr/boards/nxp/frdm_rw612/frdm_rw612_common.dtsi:299 */
				pinctrl-0 = < &pinmux_flexcomm2_i2c >;                 /* in zephyr/boards/nxp/frdm_rw612/frdm_rw612_common.dtsi:300 */
				pinctrl-names = "default";                             /* in zephyr/boards/nxp/frdm_rw612/frdm_rw612_common.dtsi:301 */
				status = "okay";                                       /* in zephyr/boards/nxp/frdm_rw612/frdm_rw612_common.dtsi:317 */

				/* node '/soc/peripheral@50000000/flexcomm@108000/p3t1755@48' defined in zephyr/boards/nxp/frdm_rw612/frdm_rw612_common.dtsi:303 */
				p3t1755: p3t1755@48 {
					compatible = "nxp,p3t1755"; /* in zephyr/boards/nxp/frdm_rw612/frdm_rw612_common.dtsi:304 */
					reg = < 0x48 >;             /* in zephyr/boards/nxp/frdm_rw612/frdm_rw612_common.dtsi:305 */
					status = "okay";            /* in zephyr/boards/nxp/frdm_rw612/frdm_rw612_common.dtsi:306 */
				};
			};

			/* node '/soc/peripheral@50000000/flexcomm@109000' defined in zephyr/dts/arm/nxp/nxp_rw6xx_common.dtsi:302 */
			flexcomm3: flexcomm@109000 {
				reg = < 0x109000 0x1000 >;                             /* in zephyr/dts/arm/nxp/nxp_rw6xx_common.dtsi:304 */
				interrupts = < 0x11 0x0 >;                             /* in zephyr/dts/arm/nxp/nxp_rw6xx_common.dtsi:305 */
				clocks = < &clkctl1 0x103 &clkctl1 0x183 >;            /* in zephyr/dts/arm/nxp/nxp_rw6xx_common.dtsi:306 */
				clock-names = "default",
				              "sleep";                                 /* in zephyr/dts/arm/nxp/nxp_rw6xx_common.dtsi:307 */
				resets = < &rstctl1 0xb >;                             /* in zephyr/dts/arm/nxp/nxp_rw6xx_common.dtsi:308 */
				dmas = < &dma0 0x6 >,
				       < &dma0 0x7 >;                                  /* in zephyr/dts/arm/nxp/nxp_rw6xx_common.dtsi:309 */
				dma-names = "rx",
				            "tx";                                      /* in zephyr/dts/arm/nxp/nxp_rw6xx_common.dtsi:310 */
				zephyr,disabling-power-states = < &suspend &standby >; /* in zephyr/dts/arm/nxp/nxp_rw6xx_common.dtsi:311 */
				power-domains = < &power_mode3_domain >;               /* in zephyr/dts/arm/nxp/nxp_rw6xx_common.dtsi:312 */
				compatible = "nxp,lpc-usart";                          /* in zephyr/boards/nxp/frdm_rw612/frdm_rw612_common.dtsi:88 */
				status = "okay";                                       /* in zephyr/boards/nxp/frdm_rw612/frdm_rw612_common.dtsi:89 */
				current-speed = < 0x1c200 >;                           /* in zephyr/boards/nxp/frdm_rw612/frdm_rw612_common.dtsi:90 */
				pinctrl-0 = < &pinmux_flexcomm3_usart >;               /* in zephyr/boards/nxp/frdm_rw612/frdm_rw612_common.dtsi:91 */
				pinctrl-names = "default";                             /* in zephyr/boards/nxp/frdm_rw612/frdm_rw612_common.dtsi:92 */
				wakeup-source;                                         /* in zephyr/boards/nxp/frdm_rw612/frdm_rw612_common.dtsi:93 */
			};

			/* node '/soc/peripheral@50000000/flexcomm@126000' defined in zephyr/dts/arm/nxp/nxp_rw6xx_common.dtsi:316 */
			flexcomm14: flexcomm@126000 {
				compatible = "nxp,lpc-flexcomm";                       /* in zephyr/dts/arm/nxp/nxp_rw6xx_common.dtsi:317 */
				reg = < 0x126000 0x2000 >;                             /* in zephyr/dts/arm/nxp/nxp_rw6xx_common.dtsi:318 */
				interrupts = < 0x14 0x0 >;                             /* in zephyr/dts/arm/nxp/nxp_rw6xx_common.dtsi:319 */
				clocks = < &clkctl1 0x10e >;                           /* in zephyr/dts/arm/nxp/nxp_rw6xx_common.dtsi:320 */
				resets = < &rstctl1 0x16 >;                            /* in zephyr/dts/arm/nxp/nxp_rw6xx_common.dtsi:321 */
				dmas = < &dma0 0x1a >,
				       < &dma0 0x1b >;                                 /* in zephyr/dts/arm/nxp/nxp_rw6xx_common.dtsi:322 */
				dma-names = "rx",
				            "tx";                                      /* in zephyr/dts/arm/nxp/nxp_rw6xx_common.dtsi:323 */
				zephyr,disabling-power-states = < &suspend &standby >; /* in zephyr/dts/arm/nxp/nxp_rw6xx_common.dtsi:324 */
				power-domains = < &power_mode3_domain >;               /* in zephyr/dts/arm/nxp/nxp_rw6xx_common.dtsi:325 */
				status = "disabled";                                   /* in zephyr/dts/arm/nxp/nxp_rw6xx_common.dtsi:326 */
			};

			/* node '/soc/peripheral@50000000/aon_soc_ctrl@5000800' defined in zephyr/dts/arm/nxp/nxp_rw6xx_common.dtsi:329 */
			aon_soc_ctrl: aon_soc_ctrl@5000800 {
				compatible = "nxp,rw-soc-ctrl"; /* in zephyr/dts/arm/nxp/nxp_rw6xx_common.dtsi:330 */
				reg = < 0x5000800 0x1000 >;     /* in zephyr/dts/arm/nxp/nxp_rw6xx_common.dtsi:331 */
				status = "okay";                /* in zephyr/dts/arm/nxp/nxp_rw6xx_common.dtsi:332 */
			};

			/* node '/soc/peripheral@50000000/soc_ctrl@5001000' defined in zephyr/dts/arm/nxp/nxp_rw6xx_common.dtsi:335 */
			soc_ctrl: soc_ctrl@5001000 {
				compatible = "nxp,rw-soc-ctrl"; /* in zephyr/dts/arm/nxp/nxp_rw6xx_common.dtsi:336 */
				reg = < 0x5001000 0x1000 >;     /* in zephyr/dts/arm/nxp/nxp_rw6xx_common.dtsi:337 */
				status = "okay";                /* in zephyr/dts/arm/nxp/nxp_rw6xx_common.dtsi:338 */
			};

			/* node '/soc/peripheral@50000000/pint@25000' defined in zephyr/dts/arm/nxp/nxp_rw6xx_common.dtsi:341 */
			pint: pint@25000 {
				compatible = "nxp,pint";                 /* in zephyr/dts/arm/nxp/nxp_rw6xx_common.dtsi:342 */
				reg = < 0x25000 0x1000 >;                /* in zephyr/dts/arm/nxp/nxp_rw6xx_common.dtsi:343 */
				interrupt-controller;                    /* in zephyr/dts/arm/nxp/nxp_rw6xx_common.dtsi:344 */
				#interrupt-cells = < 0x1 >;              /* in zephyr/dts/arm/nxp/nxp_rw6xx_common.dtsi:345 */
				#address-cells = < 0x0 >;                /* in zephyr/dts/arm/nxp/nxp_rw6xx_common.dtsi:346 */
				interrupts = < 0x4 0x2 >,
				             < 0x5 0x2 >,
				             < 0x6 0x2 >,
				             < 0x7 0x2 >,
				             < 0x23 0x2 >,
				             < 0x24 0x2 >,
				             < 0x25 0x2 >,
				             < 0x26 0x2 >;               /* in zephyr/dts/arm/nxp/nxp_rw6xx_common.dtsi:347 */
				num-lines = < 0x8 >;                     /* in zephyr/dts/arm/nxp/nxp_rw6xx_common.dtsi:349 */
				num-inputs = < 0x40 >;                   /* in zephyr/dts/arm/nxp/nxp_rw6xx_common.dtsi:350 */
				power-domains = < &power_mode3_domain >; /* in zephyr/dts/arm/nxp/nxp_rw6xx_common.dtsi:351 */
			};

			/* node '/soc/peripheral@50000000/nxp_wifi' defined in zephyr/dts/arm/nxp/nxp_rw6xx_common.dtsi:354 */
			imu: nxp_wifi {
				compatible = "nxp,wifi";                 /* in zephyr/dts/arm/nxp/nxp_rw6xx_common.dtsi:355 */
				interrupts = < 0x48 0x2 >,
				             < 0x40 0x2 >;               /* in zephyr/dts/arm/nxp/nxp_rw6xx_common.dtsi:357 */
				power-domains = < &power_mode3_domain >; /* in zephyr/dts/arm/nxp/nxp_rw6xx_common.dtsi:358 */
				status = "okay";                         /* in zephyr/boards/nxp/frdm_rw612/frdm_rw612_common.dtsi:271 */
				wakeup-source;                           /* in zephyr/boards/nxp/frdm_rw612/frdm_rw612_common.dtsi:272 */
			};

			/* node '/soc/peripheral@50000000/dma-controller@104000' defined in zephyr/dts/arm/nxp/nxp_rw6xx_common.dtsi:361 */
			dma0: dma-controller@104000 {
				compatible = "nxp,lpc-dma";              /* in zephyr/dts/arm/nxp/nxp_rw6xx_common.dtsi:362 */
				reg = < 0x104000 0x1000 >;               /* in zephyr/dts/arm/nxp/nxp_rw6xx_common.dtsi:363 */
				interrupts = < 0x1 0x0 >;                /* in zephyr/dts/arm/nxp/nxp_rw6xx_common.dtsi:364 */
				#dma-cells = < 0x1 >;                    /* in zephyr/dts/arm/nxp/nxp_rw6xx_common.dtsi:366 */
				dma-channels = < 0x21 >;                 /* in zephyr/dts/arm/nxp/nxp_rw6xx_common.dtsi:367 */
				power-domains = < &power_mode3_domain >; /* in zephyr/dts/arm/nxp/nxp_rw6xx_common.dtsi:368 */
				status = "okay";                         /* in zephyr/boards/nxp/frdm_rw612/frdm_rw612_common.dtsi:217 */
				phandle = < 0x7 >;                       /* in zephyr/dts/arm/nxp/nxp_rw6xx_common.dtsi:267 */
			};

			/* node '/soc/peripheral@50000000/lcdic@128000' defined in zephyr/dts/arm/nxp/nxp_rw6xx_common.dtsi:371 */
			lcdic: zephyr_mipi_dbi_spi: lcdic@128000 {
				compatible = "nxp,lcdic";                              /* in zephyr/dts/arm/nxp/nxp_rw6xx_common.dtsi:372 */
				reg = < 0x128000 0x52 >;                               /* in zephyr/dts/arm/nxp/nxp_rw6xx_common.dtsi:373 */
				interrupts = < 0x3d 0x0 >;                             /* in zephyr/dts/arm/nxp/nxp_rw6xx_common.dtsi:374 */
				#address-cells = < 0x1 >;                              /* in zephyr/dts/arm/nxp/nxp_rw6xx_common.dtsi:376 */
				#size-cells = < 0x0 >;                                 /* in zephyr/dts/arm/nxp/nxp_rw6xx_common.dtsi:377 */
				clocks = < &clkctl1 0xe00 >;                           /* in zephyr/dts/arm/nxp/nxp_rw6xx_common.dtsi:378 */
				dmas = < &dma0 0x0 >;                                  /* in zephyr/dts/arm/nxp/nxp_rw6xx_common.dtsi:379 */
				zephyr,disabling-power-states = < &suspend &standby >; /* in zephyr/dts/arm/nxp/nxp_rw6xx_common.dtsi:380 */
				power-domains = < &power_mode3_domain >;               /* in zephyr/dts/arm/nxp/nxp_rw6xx_common.dtsi:381 */
				status = "okay";                                       /* in zephyr/boards/nxp/frdm_rw612/frdm_rw612_common.dtsi:311 */
				pinctrl-0 = < &pinmux_lcdic >;                         /* in zephyr/boards/nxp/frdm_rw612/frdm_rw612_common.dtsi:312 */
				pinctrl-names = "default";                             /* in zephyr/boards/nxp/frdm_rw612/frdm_rw612_common.dtsi:313 */
			};

			/* node '/soc/peripheral@50000000/rtc@30000' defined in zephyr/dts/arm/nxp/nxp_rw6xx_common.dtsi:384 */
			rtc: rtc@30000 {
				compatible = "nxp,lpc-rtc"; /* in zephyr/dts/arm/nxp/nxp_rw6xx_common.dtsi:385 */
				reg = < 0x30000 0x1000 >;   /* in zephyr/dts/arm/nxp/nxp_rw6xx_common.dtsi:386 */
				interrupts = < 0x20 0x0 >;  /* in zephyr/dts/arm/nxp/nxp_rw6xx_common.dtsi:387 */
				status = "disabled";        /* in zephyr/dts/arm/nxp/nxp_rw6xx_common.dtsi:388 */

				/* node '/soc/peripheral@50000000/rtc@30000/rtc_highres' defined in zephyr/dts/arm/nxp/nxp_rw6xx_common.dtsi:389 */
				rtc_highres: rtc_highres {
					compatible = "nxp,lpc-rtc-highres"; /* in zephyr/dts/arm/nxp/nxp_rw6xx_common.dtsi:390 */
					status = "okay";                    /* in zephyr/boards/nxp/frdm_rw612/frdm_rw612_common.dtsi:261 */
					wakeup-source;                      /* in zephyr/boards/nxp/frdm_rw612/frdm_rw612_common.dtsi:262 */
					phandle = < 0x11 >;                 /* in zephyr/boards/nxp/frdm_rw612/frdm_rw612_common.dtsi:238 */
				};
			};

			/* node '/soc/peripheral@50000000/ctimer@28000' defined in zephyr/dts/arm/nxp/nxp_rw6xx_common.dtsi:395 */
			ctimer0: ctimer@28000 {
				compatible = "nxp,lpc-ctimer";           /* in zephyr/dts/arm/nxp/nxp_rw6xx_common.dtsi:396 */
				reg = < 0x28000 0x1000 >;                /* in zephyr/dts/arm/nxp/nxp_rw6xx_common.dtsi:397 */
				interrupts = < 0xa 0x0 >;                /* in zephyr/dts/arm/nxp/nxp_rw6xx_common.dtsi:398 */
				clk-source = < 0x1 >;                    /* in zephyr/dts/arm/nxp/nxp_rw6xx_common.dtsi:400 */
				clocks = < &clkctl1 0x0 >;               /* in zephyr/dts/arm/nxp/nxp_rw6xx_common.dtsi:401 */
				mode = < 0x0 >;                          /* in zephyr/dts/arm/nxp/nxp_rw6xx_common.dtsi:402 */
				input = < 0x0 >;                         /* in zephyr/dts/arm/nxp/nxp_rw6xx_common.dtsi:403 */
				prescale = < 0x0 >;                      /* in zephyr/dts/arm/nxp/nxp_rw6xx_common.dtsi:404 */
				power-domains = < &power_mode3_domain >; /* in zephyr/dts/arm/nxp/nxp_rw6xx_common.dtsi:405 */
				status = "okay";                         /* in zephyr/boards/nxp/frdm_rw612/frdm_rw612_common.dtsi:225 */
			};

			/* node '/soc/peripheral@50000000/ctimer@29000' defined in zephyr/dts/arm/nxp/nxp_rw6xx_common.dtsi:408 */
			ctimer1: ctimer@29000 {
				compatible = "nxp,lpc-ctimer";           /* in zephyr/dts/arm/nxp/nxp_rw6xx_common.dtsi:409 */
				reg = < 0x29000 0x1000 >;                /* in zephyr/dts/arm/nxp/nxp_rw6xx_common.dtsi:410 */
				interrupts = < 0xb 0x0 >;                /* in zephyr/dts/arm/nxp/nxp_rw6xx_common.dtsi:411 */
				status = "disabled";                     /* in zephyr/dts/arm/nxp/nxp_rw6xx_common.dtsi:412 */
				clk-source = < 0x1 >;                    /* in zephyr/dts/arm/nxp/nxp_rw6xx_common.dtsi:413 */
				clocks = < &clkctl1 0x1 >;               /* in zephyr/dts/arm/nxp/nxp_rw6xx_common.dtsi:414 */
				mode = < 0x0 >;                          /* in zephyr/dts/arm/nxp/nxp_rw6xx_common.dtsi:415 */
				input = < 0x0 >;                         /* in zephyr/dts/arm/nxp/nxp_rw6xx_common.dtsi:416 */
				prescale = < 0x0 >;                      /* in zephyr/dts/arm/nxp/nxp_rw6xx_common.dtsi:417 */
				power-domains = < &power_mode3_domain >; /* in zephyr/dts/arm/nxp/nxp_rw6xx_common.dtsi:418 */
			};

			/* node '/soc/peripheral@50000000/ctimer@2a000' defined in zephyr/dts/arm/nxp/nxp_rw6xx_common.dtsi:421 */
			ctimer2: ctimer@2a000 {
				compatible = "nxp,lpc-ctimer";           /* in zephyr/dts/arm/nxp/nxp_rw6xx_common.dtsi:422 */
				reg = < 0x2a000 0x1000 >;                /* in zephyr/dts/arm/nxp/nxp_rw6xx_common.dtsi:423 */
				interrupts = < 0x27 0x0 >;               /* in zephyr/dts/arm/nxp/nxp_rw6xx_common.dtsi:424 */
				status = "disabled";                     /* in zephyr/dts/arm/nxp/nxp_rw6xx_common.dtsi:425 */
				clk-source = < 0x1 >;                    /* in zephyr/dts/arm/nxp/nxp_rw6xx_common.dtsi:426 */
				clocks = < &clkctl1 0x2 >;               /* in zephyr/dts/arm/nxp/nxp_rw6xx_common.dtsi:427 */
				mode = < 0x0 >;                          /* in zephyr/dts/arm/nxp/nxp_rw6xx_common.dtsi:428 */
				input = < 0x0 >;                         /* in zephyr/dts/arm/nxp/nxp_rw6xx_common.dtsi:429 */
				prescale = < 0x0 >;                      /* in zephyr/dts/arm/nxp/nxp_rw6xx_common.dtsi:430 */
				power-domains = < &power_mode3_domain >; /* in zephyr/dts/arm/nxp/nxp_rw6xx_common.dtsi:431 */
			};

			/* node '/soc/peripheral@50000000/ctimer@2b000' defined in zephyr/dts/arm/nxp/nxp_rw6xx_common.dtsi:434 */
			ctimer3: ctimer@2b000 {
				compatible = "nxp,lpc-ctimer";           /* in zephyr/dts/arm/nxp/nxp_rw6xx_common.dtsi:435 */
				reg = < 0x2b000 0x1000 >;                /* in zephyr/dts/arm/nxp/nxp_rw6xx_common.dtsi:436 */
				interrupts = < 0xd 0x0 >;                /* in zephyr/dts/arm/nxp/nxp_rw6xx_common.dtsi:437 */
				status = "disabled";                     /* in zephyr/dts/arm/nxp/nxp_rw6xx_common.dtsi:438 */
				clk-source = < 0x1 >;                    /* in zephyr/dts/arm/nxp/nxp_rw6xx_common.dtsi:439 */
				clocks = < &clkctl1 0x3 >;               /* in zephyr/dts/arm/nxp/nxp_rw6xx_common.dtsi:440 */
				mode = < 0x0 >;                          /* in zephyr/dts/arm/nxp/nxp_rw6xx_common.dtsi:441 */
				input = < 0x0 >;                         /* in zephyr/dts/arm/nxp/nxp_rw6xx_common.dtsi:442 */
				prescale = < 0x0 >;                      /* in zephyr/dts/arm/nxp/nxp_rw6xx_common.dtsi:443 */
				power-domains = < &power_mode3_domain >; /* in zephyr/dts/arm/nxp/nxp_rw6xx_common.dtsi:444 */
			};

			/* node '/soc/peripheral@50000000/pwm@146000' defined in zephyr/dts/arm/nxp/nxp_rw6xx_common.dtsi:447 */
			sctimer: pwm@146000 {
				compatible = "nxp,sctimer-pwm";          /* in zephyr/dts/arm/nxp/nxp_rw6xx_common.dtsi:448 */
				reg = < 0x146000 0x1000 >;               /* in zephyr/dts/arm/nxp/nxp_rw6xx_common.dtsi:449 */
				interrupts = < 0xc 0x0 >;                /* in zephyr/dts/arm/nxp/nxp_rw6xx_common.dtsi:450 */
				clocks = < &clkctl1 0x900 >;             /* in zephyr/dts/arm/nxp/nxp_rw6xx_common.dtsi:451 */
				prescaler = < 0x8 >;                     /* in zephyr/dts/arm/nxp/nxp_rw6xx_common.dtsi:453 */
				#pwm-cells = < 0x3 >;                    /* in zephyr/dts/arm/nxp/nxp_rw6xx_common.dtsi:454 */
				power-domains = < &power_mode3_domain >; /* in zephyr/dts/arm/nxp/nxp_rw6xx_common.dtsi:455 */
				status = "okay";                         /* in zephyr/boards/nxp/frdm_rw612/frdm_rw612_common.dtsi:254 */
				pinctrl-0 = < &pinmux_pwm0 >;            /* in zephyr/boards/nxp/frdm_rw612/frdm_rw612_common.dtsi:255 */
				pinctrl-names = "default";               /* in zephyr/boards/nxp/frdm_rw612/frdm_rw612_common.dtsi:256 */
			};

			/* node '/soc/peripheral@50000000/mrt@2d000' defined in zephyr/dts/arm/nxp/nxp_rw6xx_common.dtsi:458 */
			mrt0: mrt@2d000 {
				compatible = "nxp,mrt";                  /* in zephyr/dts/arm/nxp/nxp_rw6xx_common.dtsi:459 */
				reg = < 0x2d000 0x100 >;                 /* in zephyr/dts/arm/nxp/nxp_rw6xx_common.dtsi:460 */
				interrupts = < 0x9 0x0 >;                /* in zephyr/dts/arm/nxp/nxp_rw6xx_common.dtsi:461 */
				num-channels = < 0x4 >;                  /* in zephyr/dts/arm/nxp/nxp_rw6xx_common.dtsi:462 */
				num-bits = < 0x18 >;                     /* in zephyr/dts/arm/nxp/nxp_rw6xx_common.dtsi:463 */
				clocks = < &clkctl1 0xb00 >;             /* in zephyr/dts/arm/nxp/nxp_rw6xx_common.dtsi:464 */
				resets = < &rstctl1 0x20008 >;           /* in zephyr/dts/arm/nxp/nxp_rw6xx_common.dtsi:465 */
				#address-cells = < 0x1 >;                /* in zephyr/dts/arm/nxp/nxp_rw6xx_common.dtsi:466 */
				#size-cells = < 0x0 >;                   /* in zephyr/dts/arm/nxp/nxp_rw6xx_common.dtsi:467 */
				power-domains = < &power_mode3_domain >; /* in zephyr/dts/arm/nxp/nxp_rw6xx_common.dtsi:468 */

				/* node '/soc/peripheral@50000000/mrt@2d000/mrt0_channel@0' defined in zephyr/dts/arm/nxp/nxp_rw6xx_common.dtsi:470 */
				mrt0_channel0: mrt0_channel@0 {
					compatible = "nxp,mrt-channel"; /* in zephyr/dts/arm/nxp/nxp_rw6xx_common.dtsi:471 */
					reg = < 0x0 >;                  /* in zephyr/dts/arm/nxp/nxp_rw6xx_common.dtsi:472 */
					status = "okay";                /* in zephyr/boards/nxp/frdm_rw612/frdm_rw612_common.dtsi:221 */
				};

				/* node '/soc/peripheral@50000000/mrt@2d000/mrt0_channel@1' defined in zephyr/dts/arm/nxp/nxp_rw6xx_common.dtsi:475 */
				mrt0_channel1: mrt0_channel@1 {
					compatible = "nxp,mrt-channel"; /* in zephyr/dts/arm/nxp/nxp_rw6xx_common.dtsi:476 */
					reg = < 0x1 >;                  /* in zephyr/dts/arm/nxp/nxp_rw6xx_common.dtsi:477 */
					status = "disabled";            /* in zephyr/dts/arm/nxp/nxp_rw6xx_common.dtsi:478 */
				};

				/* node '/soc/peripheral@50000000/mrt@2d000/mrt0_channel@2' defined in zephyr/dts/arm/nxp/nxp_rw6xx_common.dtsi:480 */
				mrt0_channel2: mrt0_channel@2 {
					compatible = "nxp,mrt-channel"; /* in zephyr/dts/arm/nxp/nxp_rw6xx_common.dtsi:481 */
					reg = < 0x2 >;                  /* in zephyr/dts/arm/nxp/nxp_rw6xx_common.dtsi:482 */
					status = "disabled";            /* in zephyr/dts/arm/nxp/nxp_rw6xx_common.dtsi:483 */
				};

				/* node '/soc/peripheral@50000000/mrt@2d000/mrt0_channel@3' defined in zephyr/dts/arm/nxp/nxp_rw6xx_common.dtsi:485 */
				mrt0_channel3: mrt0_channel@3 {
					compatible = "nxp,mrt-channel"; /* in zephyr/dts/arm/nxp/nxp_rw6xx_common.dtsi:486 */
					reg = < 0x3 >;                  /* in zephyr/dts/arm/nxp/nxp_rw6xx_common.dtsi:487 */
					status = "disabled";            /* in zephyr/dts/arm/nxp/nxp_rw6xx_common.dtsi:488 */
				};
			};

			/* node '/soc/peripheral@50000000/mrt@3f000' defined in zephyr/dts/arm/nxp/nxp_rw6xx_common.dtsi:492 */
			mrt1: mrt@3f000 {
				compatible = "nxp,mrt";                  /* in zephyr/dts/arm/nxp/nxp_rw6xx_common.dtsi:493 */
				reg = < 0x3f000 0x100 >;                 /* in zephyr/dts/arm/nxp/nxp_rw6xx_common.dtsi:494 */
				interrupts = < 0x17 0x0 >;               /* in zephyr/dts/arm/nxp/nxp_rw6xx_common.dtsi:495 */
				num-channels = < 0x4 >;                  /* in zephyr/dts/arm/nxp/nxp_rw6xx_common.dtsi:496 */
				num-bits = < 0x18 >;                     /* in zephyr/dts/arm/nxp/nxp_rw6xx_common.dtsi:497 */
				clocks = < &clkctl1 0xb01 >;             /* in zephyr/dts/arm/nxp/nxp_rw6xx_common.dtsi:498 */
				resets = < &rstctl0 0x2001a >;           /* in zephyr/dts/arm/nxp/nxp_rw6xx_common.dtsi:499 */
				#address-cells = < 0x1 >;                /* in zephyr/dts/arm/nxp/nxp_rw6xx_common.dtsi:500 */
				#size-cells = < 0x0 >;                   /* in zephyr/dts/arm/nxp/nxp_rw6xx_common.dtsi:501 */
				power-domains = < &power_mode3_domain >; /* in zephyr/dts/arm/nxp/nxp_rw6xx_common.dtsi:502 */

				/* node '/soc/peripheral@50000000/mrt@3f000/mrt1_channel@0' defined in zephyr/dts/arm/nxp/nxp_rw6xx_common.dtsi:504 */
				mrt1_channel0: mrt1_channel@0 {
					compatible = "nxp,mrt-channel"; /* in zephyr/dts/arm/nxp/nxp_rw6xx_common.dtsi:505 */
					reg = < 0x0 >;                  /* in zephyr/dts/arm/nxp/nxp_rw6xx_common.dtsi:506 */
					status = "disabled";            /* in zephyr/dts/arm/nxp/nxp_rw6xx_common.dtsi:507 */
				};

				/* node '/soc/peripheral@50000000/mrt@3f000/mrt1_channel@1' defined in zephyr/dts/arm/nxp/nxp_rw6xx_common.dtsi:509 */
				mrt1_channel1: mrt1_channel@1 {
					compatible = "nxp,mrt-channel"; /* in zephyr/dts/arm/nxp/nxp_rw6xx_common.dtsi:510 */
					reg = < 0x1 >;                  /* in zephyr/dts/arm/nxp/nxp_rw6xx_common.dtsi:511 */
					status = "disabled";            /* in zephyr/dts/arm/nxp/nxp_rw6xx_common.dtsi:512 */
				};

				/* node '/soc/peripheral@50000000/mrt@3f000/mrt1_channel@2' defined in zephyr/dts/arm/nxp/nxp_rw6xx_common.dtsi:514 */
				mrt1_channel2: mrt1_channel@2 {
					compatible = "nxp,mrt-channel"; /* in zephyr/dts/arm/nxp/nxp_rw6xx_common.dtsi:515 */
					reg = < 0x2 >;                  /* in zephyr/dts/arm/nxp/nxp_rw6xx_common.dtsi:516 */
					status = "disabled";            /* in zephyr/dts/arm/nxp/nxp_rw6xx_common.dtsi:517 */
				};

				/* node '/soc/peripheral@50000000/mrt@3f000/mrt1_channel@3' defined in zephyr/dts/arm/nxp/nxp_rw6xx_common.dtsi:519 */
				mrt1_channel3: mrt1_channel@3 {
					compatible = "nxp,mrt-channel"; /* in zephyr/dts/arm/nxp/nxp_rw6xx_common.dtsi:520 */
					reg = < 0x3 >;                  /* in zephyr/dts/arm/nxp/nxp_rw6xx_common.dtsi:521 */
					status = "disabled";            /* in zephyr/dts/arm/nxp/nxp_rw6xx_common.dtsi:522 */
				};
			};

			/* node '/soc/peripheral@50000000/dmic@121000' defined in zephyr/dts/arm/nxp/nxp_rw6xx_common.dtsi:526 */
			dmic0: dmic@121000 {
				#address-cells = < 0x1 >;                /* in zephyr/dts/arm/nxp/nxp_rw6xx_common.dtsi:527 */
				#size-cells = < 0x0 >;                   /* in zephyr/dts/arm/nxp/nxp_rw6xx_common.dtsi:528 */
				compatible = "nxp,dmic";                 /* in zephyr/dts/arm/nxp/nxp_rw6xx_common.dtsi:529 */
				reg = < 0x121000 0x1000 >;               /* in zephyr/dts/arm/nxp/nxp_rw6xx_common.dtsi:530 */
				interrupts = < 0x19 0x0 >;               /* in zephyr/dts/arm/nxp/nxp_rw6xx_common.dtsi:531 */
				status = "disabled";                     /* in zephyr/dts/arm/nxp/nxp_rw6xx_common.dtsi:532 */
				clocks = < &clkctl1 0xa00 >;             /* in zephyr/dts/arm/nxp/nxp_rw6xx_common.dtsi:533 */
				power-domains = < &power_mode3_domain >; /* in zephyr/dts/arm/nxp/nxp_rw6xx_common.dtsi:534 */

				/* node '/soc/peripheral@50000000/dmic@121000/dmic-channel@0' defined in zephyr/dts/arm/nxp/nxp_rw6xx_common.dtsi:536 */
				pdmc0: dmic-channel@0 {
					reg = < 0x0 >;         /* in zephyr/dts/arm/nxp/nxp_rw6xx_common.dtsi:537 */
					dmas = < &dma0 0x10 >; /* in zephyr/dts/arm/nxp/nxp_rw6xx_common.dtsi:538 */
					status = "disabled";   /* in zephyr/dts/arm/nxp/nxp_rw6xx_common.dtsi:539 */
				};

				/* node '/soc/peripheral@50000000/dmic@121000/dmic-channel@1' defined in zephyr/dts/arm/nxp/nxp_rw6xx_common.dtsi:542 */
				pdmc1: dmic-channel@1 {
					reg = < 0x1 >;         /* in zephyr/dts/arm/nxp/nxp_rw6xx_common.dtsi:543 */
					dmas = < &dma0 0x11 >; /* in zephyr/dts/arm/nxp/nxp_rw6xx_common.dtsi:544 */
					status = "disabled";   /* in zephyr/dts/arm/nxp/nxp_rw6xx_common.dtsi:545 */
				};

				/* node '/soc/peripheral@50000000/dmic@121000/dmic-channel@2' defined in zephyr/dts/arm/nxp/nxp_rw6xx_common.dtsi:548 */
				pdmc2: dmic-channel@2 {
					reg = < 0x2 >;         /* in zephyr/dts/arm/nxp/nxp_rw6xx_common.dtsi:549 */
					dmas = < &dma0 0x12 >; /* in zephyr/dts/arm/nxp/nxp_rw6xx_common.dtsi:550 */
					status = "disabled";   /* in zephyr/dts/arm/nxp/nxp_rw6xx_common.dtsi:551 */
				};

				/* node '/soc/peripheral@50000000/dmic@121000/dmic-channel@3' defined in zephyr/dts/arm/nxp/nxp_rw6xx_common.dtsi:554 */
				pdmc3: dmic-channel@3 {
					reg = < 0x3 >;         /* in zephyr/dts/arm/nxp/nxp_rw6xx_common.dtsi:555 */
					dmas = < &dma0 0x13 >; /* in zephyr/dts/arm/nxp/nxp_rw6xx_common.dtsi:556 */
					status = "disabled";   /* in zephyr/dts/arm/nxp/nxp_rw6xx_common.dtsi:557 */
				};
			};

			/* node '/soc/peripheral@50000000/gau' defined in zephyr/dts/arm/nxp/nxp_rw6xx_common.dtsi:561 */
			gau {
				ranges;                   /* in zephyr/dts/arm/nxp/nxp_rw6xx_common.dtsi:562 */
				#address-cells = < 0x1 >; /* in zephyr/dts/arm/nxp/nxp_rw6xx_common.dtsi:563 */
				#size-cells = < 0x1 >;    /* in zephyr/dts/arm/nxp/nxp_rw6xx_common.dtsi:564 */

				/* node '/soc/peripheral@50000000/gau/gau_adc0@38000' defined in zephyr/dts/arm/nxp/nxp_rw6xx_common.dtsi:566 */
				adc0: gau_adc0@38000 {
					compatible = "nxp,gau-adc";              /* in zephyr/dts/arm/nxp/nxp_rw6xx_common.dtsi:567 */
					reg = < 0x38000 0x100 >;                 /* in zephyr/dts/arm/nxp/nxp_rw6xx_common.dtsi:568 */
					interrupts = < 0x70 0x0 >;               /* in zephyr/dts/arm/nxp/nxp_rw6xx_common.dtsi:569 */
					#io-channel-cells = < 0x1 >;             /* in zephyr/dts/arm/nxp/nxp_rw6xx_common.dtsi:571 */
					power-domains = < &power_mode3_domain >; /* in zephyr/dts/arm/nxp/nxp_rw6xx_common.dtsi:572 */
					status = "okay";                         /* in zephyr/boards/nxp/frdm_rw612/frdm_rw612_common.dtsi:246 */
				};

				/* node '/soc/peripheral@50000000/gau/gau_adc1@38100' defined in zephyr/dts/arm/nxp/nxp_rw6xx_common.dtsi:575 */
				adc1: gau_adc1@38100 {
					compatible = "nxp,gau-adc";              /* in zephyr/dts/arm/nxp/nxp_rw6xx_common.dtsi:576 */
					reg = < 0x38100 0x100 >;                 /* in zephyr/dts/arm/nxp/nxp_rw6xx_common.dtsi:577 */
					interrupts = < 0x6f 0x0 >;               /* in zephyr/dts/arm/nxp/nxp_rw6xx_common.dtsi:578 */
					status = "disabled";                     /* in zephyr/dts/arm/nxp/nxp_rw6xx_common.dtsi:579 */
					#io-channel-cells = < 0x1 >;             /* in zephyr/dts/arm/nxp/nxp_rw6xx_common.dtsi:580 */
					power-domains = < &power_mode3_domain >; /* in zephyr/dts/arm/nxp/nxp_rw6xx_common.dtsi:581 */
				};

				/* node '/soc/peripheral@50000000/gau/dac@38200' defined in zephyr/dts/arm/nxp/nxp_rw6xx_common.dtsi:584 */
				dac0: dac@38200 {
					compatible = "nxp,gau-dac";              /* in zephyr/dts/arm/nxp/nxp_rw6xx_common.dtsi:585 */
					reg = < 0x38200 0x30 >;                  /* in zephyr/dts/arm/nxp/nxp_rw6xx_common.dtsi:586 */
					interrupts = < 0x6c 0x0 >;               /* in zephyr/dts/arm/nxp/nxp_rw6xx_common.dtsi:587 */
					#io-channel-cells = < 0x0 >;             /* in zephyr/dts/arm/nxp/nxp_rw6xx_common.dtsi:589 */
					power-domains = < &power_mode3_domain >; /* in zephyr/dts/arm/nxp/nxp_rw6xx_common.dtsi:590 */
					status = "okay";                         /* in zephyr/boards/nxp/frdm_rw612/frdm_rw612_common.dtsi:250 */
				};
			};

			/* node '/soc/peripheral@50000000/timers@13b000' defined in zephyr/dts/arm/nxp/nxp_rw6xx_common.dtsi:594 */
			os_timer: timers@13b000 {
				compatible = "nxp,os-timer";           /* in zephyr/dts/arm/nxp/nxp_rw6xx_common.dtsi:595 */
				reg = < 0x13b000 0x1000 >;             /* in zephyr/dts/arm/nxp/nxp_rw6xx_common.dtsi:596 */
				interrupts = < 0x29 0x0 >;             /* in zephyr/dts/arm/nxp/nxp_rw6xx_common.dtsi:597 */
				status = "okay";                       /* in zephyr/boards/nxp/frdm_rw612/frdm_rw612_common.dtsi:236 */
				wakeup-source;                         /* in zephyr/boards/nxp/frdm_rw612/frdm_rw612_common.dtsi:237 */
				deep-sleep-counter = < &rtc_highres >; /* in zephyr/boards/nxp/frdm_rw612/frdm_rw612_common.dtsi:238 */
			};

			/* node '/soc/peripheral@50000000/nbu' defined in zephyr/dts/arm/nxp/nxp_rw6xx_common.dtsi:601 */
			nbu: nbu {
				compatible = "nxp,nbu";         /* in zephyr/dts/arm/nxp/nxp_rw6xx_common.dtsi:602 */
				interrupts = < 0x5a 0x2 >,
				             < 0x52 0x2 >;      /* in zephyr/dts/arm/nxp/nxp_rw6xx_common.dtsi:603 */
				interrupt-names = "nbu_rx_int",
				                  "wakeup_int"; /* in zephyr/dts/arm/nxp/nxp_rw6xx_common.dtsi:604 */
				status = "okay";                /* in zephyr/boards/nxp/frdm_rw612/frdm_rw612_common.dtsi:266 */
				wakeup-source;                  /* in zephyr/boards/nxp/frdm_rw612/frdm_rw612_common.dtsi:267 */
			};

			/* node '/soc/peripheral@50000000/hci_ble' defined in zephyr/dts/arm/nxp/nxp_rw6xx_common.dtsi:607 */
			hci: hci_ble {
				compatible = "nxp,hci-ble";              /* in zephyr/dts/arm/nxp/nxp_rw6xx_common.dtsi:608 */
				power-domains = < &power_mode3_domain >; /* in zephyr/dts/arm/nxp/nxp_rw6xx_common.dtsi:609 */
				status = "okay";                         /* in zephyr/boards/nxp/frdm_rw612/frdm_rw612_common.dtsi:185 */
				wakeup-source;                           /* in zephyr/boards/nxp/frdm_rw612/frdm_rw612_common.dtsi:186 */
			};

			/* node '/soc/peripheral@50000000/hdlc_rcp_if' defined in zephyr/dts/arm/nxp/nxp_rw6xx_common.dtsi:612 */
			hdlc_rcp_if: hdlc_rcp_if {
				compatible = "nxp,hdlc-rcp-if";          /* in zephyr/dts/arm/nxp/nxp_rw6xx_common.dtsi:613 */
				interrupts = < 0x5a 0x2 >,
				             < 0x52 0x2 >;               /* in zephyr/dts/arm/nxp/nxp_rw6xx_common.dtsi:614 */
				interrupt-names = "hdlc_rcp_if_int",
				                  "wakeup_int";          /* in zephyr/dts/arm/nxp/nxp_rw6xx_common.dtsi:615 */
				power-domains = < &power_mode3_domain >; /* in zephyr/dts/arm/nxp/nxp_rw6xx_common.dtsi:616 */
			};

			/* node '/soc/peripheral@50000000/enet@138000' defined in zephyr/dts/arm/nxp/nxp_rw6xx_common.dtsi:619 */
			enet: enet@138000 {
				compatible = "nxp,enet";     /* in zephyr/dts/arm/nxp/nxp_rw6xx_common.dtsi:620 */
				reg = < 0x138000 0x700 >;    /* in zephyr/dts/arm/nxp/nxp_rw6xx_common.dtsi:621 */
				clocks = < &clkctl1 0xd80 >; /* in zephyr/dts/arm/nxp/nxp_rw6xx_common.dtsi:622 */

				/* node '/soc/peripheral@50000000/enet@138000/ethernet' defined in zephyr/dts/arm/nxp/nxp_rw6xx_common.dtsi:623 */
				enet_mac: ethernet {
					compatible = "nxp,enet-mac";             /* in zephyr/dts/arm/nxp/nxp_rw6xx_common.dtsi:624 */
					interrupts = < 0x73 0x0 >;               /* in zephyr/dts/arm/nxp/nxp_rw6xx_common.dtsi:625 */
					interrupt-names = "COMMON";              /* in zephyr/dts/arm/nxp/nxp_rw6xx_common.dtsi:626 */
					nxp,mdio = < &enet_mdio >;               /* in zephyr/dts/arm/nxp/nxp_rw6xx_common.dtsi:627 */
					ptp-clock = < &enet_ptp_clock >;         /* in zephyr/dts/arm/nxp/nxp_rw6xx_common.dtsi:628 */
					power-domains = < &power_mode3_domain >; /* in zephyr/dts/arm/nxp/nxp_rw6xx_common.dtsi:630 */
					status = "okay";                         /* in zephyr/boards/nxp/frdm_rw612/frdm_rw612_common.dtsi:190 */
					pinctrl-0 = < &pinmux_enet >;            /* in zephyr/boards/nxp/frdm_rw612/frdm_rw612_common.dtsi:191 */
					pinctrl-names = "default";               /* in zephyr/boards/nxp/frdm_rw612/frdm_rw612_common.dtsi:192 */
					phy-handle = < &phy >;                   /* in zephyr/boards/nxp/frdm_rw612/frdm_rw612_common.dtsi:193 */
					nxp,unique-mac;                          /* in zephyr/boards/nxp/frdm_rw612/frdm_rw612_common.dtsi:194 */
					phy-connection-type = "rmii";            /* in zephyr/boards/nxp/frdm_rw612/frdm_rw612_common.dtsi:195 */
				};

				/* node '/soc/peripheral@50000000/enet@138000/mdio' defined in zephyr/dts/arm/nxp/nxp_rw6xx_common.dtsi:632 */
				enet_mdio: mdio {
					compatible = "nxp,enet-mdio";            /* in zephyr/dts/arm/nxp/nxp_rw6xx_common.dtsi:633 */
					#address-cells = < 0x1 >;                /* in zephyr/dts/arm/nxp/nxp_rw6xx_common.dtsi:635 */
					#size-cells = < 0x0 >;                   /* in zephyr/dts/arm/nxp/nxp_rw6xx_common.dtsi:636 */
					power-domains = < &power_mode3_domain >; /* in zephyr/dts/arm/nxp/nxp_rw6xx_common.dtsi:637 */
					status = "okay";                         /* in zephyr/boards/nxp/frdm_rw612/frdm_rw612_common.dtsi:199 */
					pinctrl-0 = < &pinmux_mdio >;            /* in zephyr/boards/nxp/frdm_rw612/frdm_rw612_common.dtsi:200 */
					pinctrl-names = "default";               /* in zephyr/boards/nxp/frdm_rw612/frdm_rw612_common.dtsi:201 */
					phandle = < 0x12 >;                      /* in zephyr/dts/arm/nxp/nxp_rw6xx_common.dtsi:627 */

					/* node '/soc/peripheral@50000000/enet@138000/mdio/phy@2' defined in zephyr/boards/nxp/frdm_rw612/frdm_rw612_common.dtsi:202 */
					phy: phy@2 {
						compatible = "microchip,ksz8081";    /* in zephyr/boards/nxp/frdm_rw612/frdm_rw612_common.dtsi:203 */
						reg = < 0x2 >;                       /* in zephyr/boards/nxp/frdm_rw612/frdm_rw612_common.dtsi:204 */
						status = "okay";                     /* in zephyr/boards/nxp/frdm_rw612/frdm_rw612_common.dtsi:205 */
						reset-gpios = < &hsgpio1 0x17 0x0 >; /* in zephyr/boards/nxp/frdm_rw612/frdm_rw612_common.dtsi:206 */
						int-gpios = < &hsgpio0 0x15 0x0 >;   /* in zephyr/boards/nxp/frdm_rw612/frdm_rw612_common.dtsi:207 */
						microchip,interface-type = "rmii";   /* in zephyr/boards/nxp/frdm_rw612/frdm_rw612_common.dtsi:208 */
						phandle = < 0x15 >;                  /* in zephyr/boards/nxp/frdm_rw612/frdm_rw612_common.dtsi:193 */
					};
				};

				/* node '/soc/peripheral@50000000/enet@138000/ptp-clock' defined in zephyr/dts/arm/nxp/nxp_rw6xx_common.dtsi:639 */
				enet_ptp_clock: ptp-clock {
					compatible = "nxp,enet-ptp-clock";       /* in zephyr/dts/arm/nxp/nxp_rw6xx_common.dtsi:640 */
					interrupts = < 0x74 0x0 >;               /* in zephyr/dts/arm/nxp/nxp_rw6xx_common.dtsi:641 */
					status = "disabled";                     /* in zephyr/dts/arm/nxp/nxp_rw6xx_common.dtsi:642 */
					clocks = < &clkctl1 0xd81 >;             /* in zephyr/dts/arm/nxp/nxp_rw6xx_common.dtsi:643 */
					power-domains = < &power_mode3_domain >; /* in zephyr/dts/arm/nxp/nxp_rw6xx_common.dtsi:644 */
					phandle = < 0x13 >;                      /* in zephyr/dts/arm/nxp/nxp_rw6xx_common.dtsi:628 */
				};
			};
		};
	};

	/* node '/cpus' defined in zephyr/dts/arm/nxp/nxp_rw6xx_common.dtsi:24 */
	cpus {
		#address-cells = < 0x1 >; /* in zephyr/dts/arm/nxp/nxp_rw6xx_common.dtsi:25 */
		#size-cells = < 0x0 >;    /* in zephyr/dts/arm/nxp/nxp_rw6xx_common.dtsi:26 */

		/* node '/cpus/cpu@0' defined in zephyr/dts/arm/nxp/nxp_rw6xx_common.dtsi:28 */
		cpu0: cpu@0 {
			compatible = "arm,cortex-m33f";                 /* in zephyr/dts/arm/nxp/nxp_rw6xx_common.dtsi:29 */
			reg = < 0x0 >;                                  /* in zephyr/dts/arm/nxp/nxp_rw6xx_common.dtsi:30 */
			#address-cells = < 0x1 >;                       /* in zephyr/dts/arm/nxp/nxp_rw6xx_common.dtsi:31 */
			#size-cells = < 0x1 >;                          /* in zephyr/dts/arm/nxp/nxp_rw6xx_common.dtsi:32 */
			cpu-power-states = < &idle &suspend &standby >; /* in zephyr/dts/arm/nxp/nxp_rw6xx_common.dtsi:33 */

			/* node '/cpus/cpu@0/mpu@e000ed90' defined in zephyr/dts/arm/nxp/nxp_rw6xx_common.dtsi:35 */
			mpu: mpu@e000ed90 {
				compatible = "arm,armv8m-mpu"; /* in zephyr/dts/arm/nxp/nxp_rw6xx_common.dtsi:36 */
				reg = < 0xe000ed90 0x40 >;     /* in zephyr/dts/arm/nxp/nxp_rw6xx_common.dtsi:37 */
			};
		};

		/* node '/cpus/power-states' defined in zephyr/dts/arm/nxp/nxp_rw6xx_common.dtsi:41 */
		power-states {

			/* node '/cpus/power-states/idle' defined in zephyr/dts/arm/nxp/nxp_rw6xx_common.dtsi:43 */
			idle: idle {
				compatible = "zephyr,power-state"; /* in zephyr/dts/arm/nxp/nxp_rw6xx_common.dtsi:44 */
				power-state-name = "runtime-idle"; /* in zephyr/dts/arm/nxp/nxp_rw6xx_common.dtsi:45 */
				min-residency-us = < 0x0 >;        /* in zephyr/dts/arm/nxp/nxp_rw6xx_common.dtsi:46 */
				exit-latency-us = < 0x0 >;         /* in zephyr/dts/arm/nxp/nxp_rw6xx_common.dtsi:47 */
				phandle = < 0x19 >;                /* in zephyr/dts/arm/nxp/nxp_rw6xx_common.dtsi:33 */
			};

			/* node '/cpus/power-states/suspend' defined in zephyr/dts/arm/nxp/nxp_rw6xx_common.dtsi:50 */
			suspend: suspend {
				compatible = "nxp,pdcfg-power",
				             "zephyr,power-state";    /* in zephyr/dts/arm/nxp/nxp_rw6xx_common.dtsi:51 */
				power-state-name = "suspend-to-idle"; /* in zephyr/dts/arm/nxp/nxp_rw6xx_common.dtsi:52 */
				min-residency-us = < 0x258 >;         /* in zephyr/dts/arm/nxp/nxp_rw6xx_common.dtsi:53 */
				exit-latency-us = < 0x0 >;            /* in zephyr/dts/arm/nxp/nxp_rw6xx_common.dtsi:54 */
				deep-sleep-config = < 0x180000 >,
				                    < 0x0 >,
				                    < 0x4 >,
				                    < 0x100 >,
				                    < 0x0 >;          /* in zephyr/dts/arm/nxp/nxp_rw6xx_common.dtsi:55 */
				phandle = < 0x8 >;                    /* in zephyr/dts/arm/nxp/nxp_rw6xx_common.dtsi:269 */
			};

			/* node '/cpus/power-states/standby' defined in zephyr/dts/arm/nxp/nxp_rw6xx_common.dtsi:62 */
			standby: standby {
				compatible = "nxp,pdcfg-power",
				             "zephyr,power-state"; /* in zephyr/dts/arm/nxp/nxp_rw6xx_common.dtsi:63 */
				power-state-name = "standby";      /* in zephyr/dts/arm/nxp/nxp_rw6xx_common.dtsi:64 */
				min-residency-us = < 0x1770 >;     /* in zephyr/dts/arm/nxp/nxp_rw6xx_common.dtsi:66 */
				exit-latency-us = < 0x0 >;         /* in zephyr/dts/arm/nxp/nxp_rw6xx_common.dtsi:67 */
				deep-sleep-config = < 0x180000 >,
				                    < 0x0 >,
				                    < 0x4 >,
				                    < 0x100 >,
				                    < 0x0 >;       /* in zephyr/dts/arm/nxp/nxp_rw6xx_common.dtsi:68 */
				status = "disabled";               /* in zephyr/dts/arm/nxp/nxp_rw6xx_common.dtsi:73 */
				phandle = < 0x9 >;                 /* in zephyr/dts/arm/nxp/nxp_rw6xx_common.dtsi:269 */
			};
		};
	};

	/* node '/sram@41380000' defined in zephyr/dts/arm/nxp/nxp_rw6xx_common.dtsi:78 */
	smu1: sram@41380000 {
		ranges = < 0x0 0x41380000 0x7f800 >; /* in zephyr/dts/arm/nxp/nxp_rw6xx_common.dtsi:79 */
		#address-cells = < 0x1 >;            /* in zephyr/dts/arm/nxp/nxp_rw6xx_common.dtsi:121 */
		#size-cells = < 0x1 >;               /* in zephyr/dts/arm/nxp/nxp_rw6xx_common.dtsi:122 */

		/* node '/sram@41380000/memory@0' defined in zephyr/dts/arm/nxp/nxp_rw6xx_common.dtsi:124 */
		smu1_data: memory@0 {
			compatible = "zephyr,memory-region",
			             "mmio-sram";            /* in zephyr/dts/arm/nxp/nxp_rw6xx_common.dtsi:125 */
			reg = < 0x0 0x7f800 >;               /* in zephyr/dts/arm/nxp/nxp_rw6xx_common.dtsi:126 */
			zephyr,memory-region = "SMU1";       /* in zephyr/dts/arm/nxp/nxp_rw6xx_common.dtsi:127 */
			zephyr,memory-attr = < 0x100000 >;   /* in zephyr/dts/arm/nxp/nxp_rw6xx_common.dtsi:128 */
		};
	};

	/* node '/sram@443C0000' defined in zephyr/dts/arm/nxp/nxp_rw6xx_common.dtsi:82 */
	smu2: sram@443C0000 {
		ranges = < 0x0 0x443c0000 0x23000 >; /* in zephyr/dts/arm/nxp/nxp_rw6xx_common.dtsi:83 */
		#address-cells = < 0x1 >;            /* in zephyr/dts/arm/nxp/nxp_rw6xx_common.dtsi:133 */
		#size-cells = < 0x1 >;               /* in zephyr/dts/arm/nxp/nxp_rw6xx_common.dtsi:134 */

		/* node '/sram@443C0000/memory@0' defined in zephyr/dts/arm/nxp/nxp_rw6xx_common.dtsi:136 */
		smu2_data: memory@0 {
			compatible = "zephyr,memory-region",
			             "mmio-sram";            /* in zephyr/dts/arm/nxp/nxp_rw6xx_common.dtsi:137 */
			reg = < 0x0 0x23000 >;               /* in zephyr/dts/arm/nxp/nxp_rw6xx_common.dtsi:138 */
			zephyr,memory-region = "SMU2";       /* in zephyr/dts/arm/nxp/nxp_rw6xx_common.dtsi:139 */
			zephyr,memory-attr = < 0x100000 >;   /* in zephyr/dts/arm/nxp/nxp_rw6xx_common.dtsi:140 */
		};
	};

	/* node '/power_mode3_domain' defined in zephyr/dts/arm/nxp/nxp_rw6xx_common.dtsi:86 */
	power_mode3_domain: power_mode3_domain {
		compatible = "power-domain-soc-state-change"; /* in zephyr/dts/arm/nxp/nxp_rw6xx_common.dtsi:87 */
		onoff-power-states = < &standby >;            /* in zephyr/dts/arm/nxp/nxp_rw6xx_common.dtsi:88 */
		#power-domain-cells = < 0x0 >;                /* in zephyr/dts/arm/nxp/nxp_rw6xx_common.dtsi:89 */
		phandle = < 0x3 >;                            /* in zephyr/dts/arm/nxp/nxp_rw6xx_common.dtsi:204 */
	};

	/* node '/xtal32' defined in zephyr/dts/arm/nxp/nxp_rw6xx_common.dtsi:92 */
	xtal32: xtal32 {
		compatible = "fixed-clock";   /* in zephyr/dts/arm/nxp/nxp_rw6xx_common.dtsi:93 */
		clock-frequency = < 0x8000 >; /* in zephyr/dts/arm/nxp/nxp_rw6xx_common.dtsi:94 */
		#clock-cells = < 0x0 >;       /* in zephyr/dts/arm/nxp/nxp_rw6xx_common.dtsi:95 */
		status = "disabled";          /* in zephyr/dts/arm/nxp/nxp_rw6xx_common.dtsi:96 */
	};

	/* node '/leds' defined in zephyr/boards/nxp/frdm_rw612/frdm_rw612_common.dtsi:34 */
	leds {
		compatible = "gpio-leds"; /* in zephyr/boards/nxp/frdm_rw612/frdm_rw612_common.dtsi:35 */

		/* node '/leds/led_1' defined in zephyr/boards/nxp/frdm_rw612/frdm_rw612_common.dtsi:36 */
		green_led: led_1 {
			gpios = < &hsgpio0 0xc 0x1 >; /* in zephyr/boards/nxp/frdm_rw612/frdm_rw612_common.dtsi:37 */
		};
	};

	/* node '/gpio_keys' defined in zephyr/boards/nxp/frdm_rw612/frdm_rw612_common.dtsi:41 */
	gpio_keys {
		compatible = "gpio-keys"; /* in zephyr/boards/nxp/frdm_rw612/frdm_rw612_common.dtsi:42 */

		/* node '/gpio_keys/button_0' defined in zephyr/boards/nxp/frdm_rw612/frdm_rw612_common.dtsi:43 */
		user_button_0: button_0 {
			label = "User SW2";            /* in zephyr/boards/nxp/frdm_rw612/frdm_rw612_common.dtsi:44 */
			gpios = < &hsgpio0 0xb 0x11 >; /* in zephyr/boards/nxp/frdm_rw612/frdm_rw612_common.dtsi:45 */
			zephyr,code = < 0xb >;         /* in zephyr/boards/nxp/frdm_rw612/frdm_rw612_common.dtsi:46 */
			status = "okay";               /* in zephyr/boards/nxp/frdm_rw612/frdm_rw612_common.dtsi:47 */
		};
	};

	/* node '/lcd-pmod-connector' defined in zephyr/boards/nxp/frdm_rw612/frdm_rw612_common.dtsi:51 */
	nxp_lcd_pmod_connector: lcd-pmod-connector {
		compatible = "nxp,lcd-pmod";               /* in zephyr/boards/nxp/frdm_rw612/frdm_rw612_common.dtsi:52 */
		#gpio-cells = < 0x2 >;                     /* in zephyr/boards/nxp/frdm_rw612/frdm_rw612_common.dtsi:53 */
		gpio-map-mask = < 0xffffffff 0xfffffff0 >; /* in zephyr/boards/nxp/frdm_rw612/frdm_rw612_common.dtsi:54 */
		gpio-map-pass-thru = < 0x0 0xf >;          /* in zephyr/boards/nxp/frdm_rw612/frdm_rw612_common.dtsi:55 */
		gpio-map = < 0xa 0x0 &hsgpio1 0xc 0x0 >,
		           < 0xc 0x0 &hsgpio0 0x12 0x0 >;  /* in zephyr/boards/nxp/frdm_rw612/frdm_rw612_common.dtsi:56 */
	};

	/* node '/arduino-connector' defined in zephyr/boards/nxp/frdm_rw612/frdm_rw612_common.dtsi:60 */
	arduino_header: arduino-connector {
		compatible = "arduino-header-r3";          /* in zephyr/boards/nxp/frdm_rw612/frdm_rw612_common.dtsi:61 */
		#gpio-cells = < 0x2 >;                     /* in zephyr/boards/nxp/frdm_rw612/frdm_rw612_common.dtsi:62 */
		gpio-map-mask = < 0xffffffff 0xffffffc0 >; /* in zephyr/boards/nxp/frdm_rw612/frdm_rw612_common.dtsi:63 */
		gpio-map-pass-thru = < 0x0 0x3f >;         /* in zephyr/boards/nxp/frdm_rw612/frdm_rw612_common.dtsi:64 */
		gpio-map = < 0x0 0x0 &hsgpio1 0xa 0x0 >,
		           < 0x1 0x0 &hsgpio1 0xb 0x0 >,
		           < 0x2 0x0 &hsgpio1 0xd 0x0 >,
		           < 0x6 0x0 &hsgpio0 0x9 0x0 >,
		           < 0x7 0x0 &hsgpio0 0x8 0x0 >,
		           < 0x8 0x0 &hsgpio0 0xb 0x0 >,
		           < 0x9 0x0 &hsgpio0 0xf 0x0 >,
		           < 0xa 0x0 &hsgpio0 0x12 0x0 >,
		           < 0xb 0x0 &hsgpio0 0x1b 0x0 >,
		           < 0xc 0x0 &hsgpio0 0x0 0x0 >,
		           < 0xd 0x0 &hsgpio0 0x14 0x0 >,
		           < 0xe 0x0 &hsgpio1 0x12 0x0 >,
		           < 0xf 0x0 &hsgpio1 0x14 0x0 >,
		           < 0x10 0x0 &hsgpio0 0x6 0x0 >,
		           < 0x11 0x0 &hsgpio0 0x9 0x0 >,
		           < 0x12 0x0 &hsgpio0 0x8 0x0 >,
		           < 0x13 0x0 &hsgpio0 0x7 0x0 >,
		           < 0x14 0x0 &hsgpio0 0x10 0x0 >,
		           < 0x15 0x0 &hsgpio0 0x11 0x0 >; /* in zephyr/boards/nxp/frdm_rw612/frdm_rw612_common.dtsi:65 */
	};
};
